VERSION ""

NS_ :

BS_:

BU_: TRAY

BO_ 3221225472 VECTOR__INDEPENDENT_SIG_MSG: 0 Vector__XXX
 SG_ Cellbal_14 : 0|1@0+ (1,0) [0|1] "" Vector__XXX
 SG_ Cellbal_13 : 0|1@0+ (1,0) [0|1] "" Vector__XXX
 SG_ Cellbal_12 : 0|1@0+ (1,0) [0|1] "" Vector__XXX
 SG_ Cellbal_11 : 0|1@0+ (1,0) [0|1] "" Vector__XXX
 SG_ Cellbal_10 : 0|1@0+ (1,0) [0|1] "" Vector__XXX
 SG_ Cellbal_09 : 0|1@0+ (1,0) [0|1] "" Vector__XXX
 SG_ Cellbal_08 : 0|1@0+ (1,0) [0|1] "" Vector__XXX
 SG_ Cellbal_07 : 0|1@0+ (1,0) [0|1] "" Vector__XXX
 SG_ Cellbal_06 : 0|1@0+ (1,0) [0|1] "" Vector__XXX
 SG_ Cellbal_05 : 0|1@0+ (1,0) [0|1] "" Vector__XXX
 SG_ Cellbal_04 : 0|1@0+ (1,0) [0|1] "" Vector__XXX
 SG_ Cellbal_03 : 0|1@0+ (1,0) [0|1] "" Vector__XXX
 SG_ Cellbal_02 : 0|1@0+ (1,0) [0|1] "" Vector__XXX
 SG_ Cellbal_01 : 0|1@0+ (1,0) [0|1] "" Vector__XXX
 SG_ Cellbal_15 : 0|1@0+ (1,0) [0|1] "" Vector__XXX
 SG_ Cellbal_14 : 0|1@0+ (1,0) [0|1] "" Vector__XXX
 SG_ Cellbal_13 : 0|1@0+ (1,0) [0|1] "" Vector__XXX
 SG_ Cellbal_12 : 0|1@0+ (1,0) [0|1] "" Vector__XXX
 SG_ Cellbal_11 : 0|1@0+ (1,0) [0|1] "" Vector__XXX
 SG_ Cellbal_10 : 0|1@0+ (1,0) [0|1] "" Vector__XXX
 SG_ Cellbal_09 : 0|1@0+ (1,0) [0|1] "" Vector__XXX
 SG_ Cellbal_08 : 0|1@0+ (1,0) [0|1] "" Vector__XXX
 SG_ Cellbal_07 : 0|1@0+ (1,0) [0|1] "" Vector__XXX
 SG_ Cellbal_06 : 0|1@0+ (1,0) [0|1] "" Vector__XXX
 SG_ Cellbal_05 : 0|1@0+ (1,0) [0|1] "" Vector__XXX
 SG_ Cellbal_04 : 0|1@0+ (1,0) [0|1] "" Vector__XXX
 SG_ Cellbal_03 : 0|1@0+ (1,0) [0|1] "" Vector__XXX
 SG_ Cellbal_02 : 0|1@0+ (1,0) [0|1] "" Vector__XXX
 SG_ Cellbal_01 : 0|1@0+ (1,0) [0|1] "" Vector__XXX
 SG_ Cellbal_15 : 0|1@0+ (1,0) [0|1] "" Vector__XXX
 SG_ Cellbal_14 : 0|1@0+ (1,0) [0|1] "" Vector__XXX
 SG_ Cellbal_13 : 0|1@0+ (1,0) [0|1] "" Vector__XXX
 SG_ Cellbal_12 : 0|1@0+ (1,0) [0|1] "" Vector__XXX
 SG_ Cellbal_11 : 0|1@0+ (1,0) [0|1] "" Vector__XXX
 SG_ Cellbal_10 : 0|1@0+ (1,0) [0|1] "" Vector__XXX
 SG_ Cellbal_09 : 0|1@0+ (1,0) [0|1] "" Vector__XXX
 SG_ Cellbal_08 : 0|1@0+ (1,0) [0|1] "" Vector__XXX
 SG_ Cellbal_07 : 0|1@0+ (1,0) [0|1] "" Vector__XXX
 SG_ Cellbal_06 : 0|1@0+ (1,0) [0|1] "" Vector__XXX
 SG_ Cellbal_05 : 0|1@0+ (1,0) [0|1] "" Vector__XXX
 SG_ Cellbal_04 : 0|1@0+ (1,0) [0|1] "" Vector__XXX
 SG_ Cellbal_03 : 0|1@0+ (1,0) [0|1] "" Vector__XXX
 SG_ Cellbal_02 : 0|1@0+ (1,0) [0|1] "" Vector__XXX
 SG_ Cellbal_01 : 0|1@0+ (1,0) [0|1] "" Vector__XXX
 SG_ Cellbal_15 : 0|1@0+ (1,0) [0|1] "" Vector__XXX
 SG_ Cellbal_14 : 0|1@0+ (1,0) [0|1] "" Vector__XXX
 SG_ Cellbal_13 : 0|1@0+ (1,0) [0|1] "" Vector__XXX
 SG_ Cellbal_12 : 0|1@0+ (1,0) [0|1] "" Vector__XXX
 SG_ Cellbal_11 : 0|1@0+ (1,0) [0|1] "" Vector__XXX
 SG_ Cellbal_10 : 0|1@0+ (1,0) [0|1] "" Vector__XXX
 SG_ Cellbal_09 : 0|1@0+ (1,0) [0|1] "" Vector__XXX
 SG_ Cellbal_08 : 0|1@0+ (1,0) [0|1] "" Vector__XXX
 SG_ Cellbal_07 : 0|1@0+ (1,0) [0|1] "" Vector__XXX
 SG_ Cellbal_06 : 0|1@0+ (1,0) [0|1] "" Vector__XXX
 SG_ Cellbal_05 : 0|1@0+ (1,0) [0|1] "" Vector__XXX
 SG_ Cellbal_04 : 0|1@0+ (1,0) [0|1] "" Vector__XXX
 SG_ Cellbal_03 : 0|1@0+ (1,0) [0|1] "" Vector__XXX
 SG_ Cellbal_02 : 0|1@0+ (1,0) [0|1] "" Vector__XXX
 SG_ Cellbal_01 : 0|1@0+ (1,0) [0|1] "" Vector__XXX
 SG_ Cellbal_15 : 0|1@0+ (1,0) [0|1] "" Vector__XXX
 SG_ Cellbal_14 : 0|1@0+ (1,0) [0|1] "" Vector__XXX
 SG_ Cellbal_13 : 0|1@0+ (1,0) [0|1] "" Vector__XXX
 SG_ Cellbal_12 : 0|1@0+ (1,0) [0|1] "" Vector__XXX
 SG_ Cellbal_11 : 0|1@0+ (1,0) [0|1] "" Vector__XXX
 SG_ Cellbal_10 : 0|1@0+ (1,0) [0|1] "" Vector__XXX
 SG_ Cellbal_09 : 0|1@0+ (1,0) [0|1] "" Vector__XXX
 SG_ Cellbal_08 : 0|1@0+ (1,0) [0|1] "" Vector__XXX
 SG_ Cellbal_07 : 0|1@0+ (1,0) [0|1] "" Vector__XXX
 SG_ Cellbal_06 : 0|1@0+ (1,0) [0|1] "" Vector__XXX
 SG_ Cellbal_05 : 0|1@0+ (1,0) [0|1] "" Vector__XXX
 SG_ Cellbal_04 : 0|1@0+ (1,0) [0|1] "" Vector__XXX
 SG_ Cellbal_03 : 0|1@0+ (1,0) [0|1] "" Vector__XXX
 SG_ Cellbal_02 : 0|1@0+ (1,0) [0|1] "" Vector__XXX
 SG_ Cellbal_01 : 0|1@0+ (1,0) [0|1] "" Vector__XXX
 SG_ Cellbal_15 : 0|1@0+ (1,0) [0|1] "" Vector__XXX
 SG_ Cellbal_14 : 0|1@0+ (1,0) [0|1] "" Vector__XXX
 SG_ Cellbal_13 : 0|1@0+ (1,0) [0|1] "" Vector__XXX
 SG_ Cellbal_12 : 0|1@0+ (1,0) [0|1] "" Vector__XXX
 SG_ Cellbal_11 : 0|1@0+ (1,0) [0|1] "" Vector__XXX
 SG_ Cellbal_10 : 0|1@0+ (1,0) [0|1] "" Vector__XXX
 SG_ Cellbal_09 : 0|1@0+ (1,0) [0|1] "" Vector__XXX
 SG_ Cellbal_08 : 0|1@0+ (1,0) [0|1] "" Vector__XXX
 SG_ Cellbal_07 : 0|1@0+ (1,0) [0|1] "" Vector__XXX
 SG_ Cellbal_06 : 0|1@0+ (1,0) [0|1] "" Vector__XXX
 SG_ Cellbal_05 : 0|1@0+ (1,0) [0|1] "" Vector__XXX
 SG_ Cellbal_04 : 0|1@0+ (1,0) [0|1] "" Vector__XXX
 SG_ Cellbal_03 : 0|1@0+ (1,0) [0|1] "" Vector__XXX
 SG_ Cellbal_02 : 0|1@0+ (1,0) [0|1] "" Vector__XXX
 SG_ Cellbal_01 : 0|1@0+ (1,0) [0|1] "" Vector__XXX
 SG_ Cellbal_15 : 0|1@0+ (1,0) [0|1] "" Vector__XXX
 SG_ Cellbal_14 : 0|1@0+ (1,0) [0|1] "" Vector__XXX
 SG_ Cellbal_13 : 0|1@0+ (1,0) [0|1] "" Vector__XXX
 SG_ Cellbal_12 : 0|1@0+ (1,0) [0|1] "" Vector__XXX
 SG_ Cellbal_11 : 0|1@0+ (1,0) [0|1] "" Vector__XXX
 SG_ Cellbal_10 : 0|1@0+ (1,0) [0|1] "" Vector__XXX
 SG_ Cellbal_09 : 0|1@0+ (1,0) [0|1] "" Vector__XXX
 SG_ Cellbal_08 : 0|1@0+ (1,0) [0|1] "" Vector__XXX
 SG_ Cellbal_07 : 0|1@0+ (1,0) [0|1] "" Vector__XXX
 SG_ Cellbal_06 : 0|1@0+ (1,0) [0|1] "" Vector__XXX
 SG_ Cellbal_05 : 0|1@0+ (1,0) [0|1] "" Vector__XXX
 SG_ Cellbal_04 : 0|1@0+ (1,0) [0|1] "" Vector__XXX
 SG_ Cellbal_03 : 0|1@0+ (1,0) [0|1] "" Vector__XXX
 SG_ Cellbal_02 : 0|1@0+ (1,0) [0|1] "" Vector__XXX
 SG_ Cellbal_01 : 0|1@0+ (1,0) [0|1] "" Vector__XXX
 SG_ Cellbal_15 : 0|1@0+ (1,0) [0|1] "" Vector__XXX
 SG_ Cellbal_14 : 0|1@0+ (1,0) [0|1] "" Vector__XXX
 SG_ Cellbal_13 : 0|1@0+ (1,0) [0|1] "" Vector__XXX
 SG_ Cellbal_12 : 0|1@0+ (1,0) [0|1] "" Vector__XXX
 SG_ Cellbal_11 : 0|1@0+ (1,0) [0|1] "" Vector__XXX
 SG_ Cellbal_10 : 0|1@0+ (1,0) [0|1] "" Vector__XXX
 SG_ Cellbal_09 : 0|1@0+ (1,0) [0|1] "" Vector__XXX
 SG_ Cellbal_08 : 0|1@0+ (1,0) [0|1] "" Vector__XXX
 SG_ Cellbal_07 : 0|1@0+ (1,0) [0|1] "" Vector__XXX
 SG_ Cellbal_06 : 0|1@0+ (1,0) [0|1] "" Vector__XXX
 SG_ Cellbal_05 : 0|1@0+ (1,0) [0|1] "" Vector__XXX
 SG_ Cellbal_04 : 0|1@0+ (1,0) [0|1] "" Vector__XXX
 SG_ Cellbal_03 : 0|1@0+ (1,0) [0|1] "" Vector__XXX
 SG_ Cellbal_02 : 0|1@0+ (1,0) [0|1] "" Vector__XXX
 SG_ Cellbal_01 : 0|1@0+ (1,0) [0|1] "" Vector__XXX
 SG_ Cellbal_15 : 0|1@0+ (1,0) [0|1] "" Vector__XXX
 SG_ Cellbal_14 : 0|1@0+ (1,0) [0|1] "" Vector__XXX
 SG_ Cellbal_13 : 0|1@0+ (1,0) [0|1] "" Vector__XXX
 SG_ Cellbal_12 : 0|1@0+ (1,0) [0|1] "" Vector__XXX
 SG_ Cellbal_11 : 0|1@0+ (1,0) [0|1] "" Vector__XXX
 SG_ Cellbal_10 : 0|1@0+ (1,0) [0|1] "" Vector__XXX
 SG_ Cellbal_09 : 0|1@0+ (1,0) [0|1] "" Vector__XXX
 SG_ Cellbal_08 : 0|1@0+ (1,0) [0|1] "" Vector__XXX
 SG_ Cellbal_07 : 0|1@0+ (1,0) [0|1] "" Vector__XXX
 SG_ Cellbal_06 : 0|1@0+ (1,0) [0|1] "" Vector__XXX
 SG_ Cellbal_05 : 0|1@0+ (1,0) [0|1] "" Vector__XXX
 SG_ Cellbal_04 : 0|1@0+ (1,0) [0|1] "" Vector__XXX
 SG_ Cellbal_03 : 0|1@0+ (1,0) [0|1] "" Vector__XXX
 SG_ Cellbal_02 : 0|1@0+ (1,0) [0|1] "" Vector__XXX
 SG_ Cellbal_01 : 0|1@0+ (1,0) [0|1] "" Vector__XXX
 SG_ Cellbal_15 : 0|1@0+ (1,0) [0|1] "" Vector__XXX
 SG_ Cellbal_14 : 0|1@0+ (1,0) [0|1] "" Vector__XXX
 SG_ Cellbal_13 : 0|1@0+ (1,0) [0|1] "" Vector__XXX
 SG_ Cellbal_12 : 0|1@0+ (1,0) [0|1] "" Vector__XXX
 SG_ Cellbal_11 : 0|1@0+ (1,0) [0|1] "" Vector__XXX
 SG_ Cellbal_10 : 0|1@0+ (1,0) [0|1] "" Vector__XXX
 SG_ Cellbal_09 : 0|1@0+ (1,0) [0|1] "" Vector__XXX
 SG_ Cellbal_08 : 0|1@0+ (1,0) [0|1] "" Vector__XXX
 SG_ Cellbal_07 : 0|1@0+ (1,0) [0|1] "" Vector__XXX
 SG_ Cellbal_06 : 0|1@0+ (1,0) [0|1] "" Vector__XXX
 SG_ Cellbal_05 : 0|1@0+ (1,0) [0|1] "" Vector__XXX
 SG_ Cellbal_04 : 0|1@0+ (1,0) [0|1] "" Vector__XXX
 SG_ Cellbal_03 : 0|1@0+ (1,0) [0|1] "" Vector__XXX
 SG_ Cellbal_02 : 0|1@0+ (1,0) [0|1] "" Vector__XXX
 SG_ Cellbal_01 : 0|1@0+ (1,0) [0|1] "" Vector__XXX
 SG_ Cellbal_15 : 0|1@0+ (1,0) [0|1] "" Vector__XXX
 SG_ Cellbal_14 : 0|1@0+ (1,0) [0|1] "" Vector__XXX
 SG_ Cellbal_13 : 0|1@0+ (1,0) [0|1] "" Vector__XXX
 SG_ Cellbal_12 : 0|1@0+ (1,0) [0|1] "" Vector__XXX
 SG_ Cellbal_11 : 0|1@0+ (1,0) [0|1] "" Vector__XXX
 SG_ Cellbal_10 : 0|1@0+ (1,0) [0|1] "" Vector__XXX
 SG_ Cellbal_09 : 0|1@0+ (1,0) [0|1] "" Vector__XXX
 SG_ Cellbal_08 : 0|1@0+ (1,0) [0|1] "" Vector__XXX
 SG_ Cellbal_07 : 0|1@0+ (1,0) [0|1] "" Vector__XXX
 SG_ Cellbal_06 : 0|1@0+ (1,0) [0|1] "" Vector__XXX
 SG_ Cellbal_05 : 0|1@0+ (1,0) [0|1] "" Vector__XXX
 SG_ Cellbal_04 : 0|1@0+ (1,0) [0|1] "" Vector__XXX
 SG_ Cellbal_03 : 0|1@0+ (1,0) [0|1] "" Vector__XXX
 SG_ Cellbal_02 : 0|1@0+ (1,0) [0|1] "" Vector__XXX
 SG_ Cellbal_01 : 0|1@0+ (1,0) [0|1] "" Vector__XXX
 SG_ Cellbal_15 : 0|1@0+ (1,0) [0|1] "" Vector__XXX
 SG_ Cellbal_14 : 0|1@0+ (1,0) [0|1] "" Vector__XXX
 SG_ Cellbal_13 : 0|1@0+ (1,0) [0|1] "" Vector__XXX
 SG_ Cellbal_12 : 0|1@0+ (1,0) [0|1] "" Vector__XXX
 SG_ Cellbal_11 : 0|1@0+ (1,0) [0|1] "" Vector__XXX
 SG_ Cellbal_10 : 0|1@0+ (1,0) [0|1] "" Vector__XXX
 SG_ Cellbal_09 : 0|1@0+ (1,0) [0|1] "" Vector__XXX
 SG_ Cellbal_08 : 0|1@0+ (1,0) [0|1] "" Vector__XXX
 SG_ Cellbal_07 : 0|1@0+ (1,0) [0|1] "" Vector__XXX
 SG_ Cellbal_06 : 0|1@0+ (1,0) [0|1] "" Vector__XXX
 SG_ Cellbal_05 : 0|1@0+ (1,0) [0|1] "" Vector__XXX
 SG_ Cellbal_04 : 0|1@0+ (1,0) [0|1] "" Vector__XXX
 SG_ Cellbal_03 : 0|1@0+ (1,0) [0|1] "" Vector__XXX
 SG_ Cellbal_02 : 0|1@0+ (1,0) [0|1] "" Vector__XXX
 SG_ Cellbal_01 : 0|1@0+ (1,0) [0|1] "" Vector__XXX
 SG_ Cellbal_15 : 0|1@0+ (1,0) [0|1] "" Vector__XXX
 SG_ Cellbal_14 : 0|1@0+ (1,0) [0|1] "" Vector__XXX
 SG_ Cellbal_13 : 0|1@0+ (1,0) [0|1] "" Vector__XXX
 SG_ Cellbal_12 : 0|1@0+ (1,0) [0|1] "" Vector__XXX
 SG_ Cellbal_11 : 0|1@0+ (1,0) [0|1] "" Vector__XXX
 SG_ Cellbal_10 : 0|1@0+ (1,0) [0|1] "" Vector__XXX
 SG_ Cellbal_09 : 0|1@0+ (1,0) [0|1] "" Vector__XXX
 SG_ Cellbal_08 : 0|1@0+ (1,0) [0|1] "" Vector__XXX
 SG_ Cellbal_07 : 0|1@0+ (1,0) [0|1] "" Vector__XXX
 SG_ Cellbal_06 : 0|1@0+ (1,0) [0|1] "" Vector__XXX
 SG_ Cellbal_05 : 0|1@0+ (1,0) [0|1] "" Vector__XXX
 SG_ Cellbal_04 : 0|1@0+ (1,0) [0|1] "" Vector__XXX
 SG_ Cellbal_03 : 0|1@0+ (1,0) [0|1] "" Vector__XXX
 SG_ Cellbal_02 : 0|1@0+ (1,0) [0|1] "" Vector__XXX
 SG_ Cellbal_01 : 0|1@0+ (1,0) [0|1] "" Vector__XXX
 SG_ Cellbal_15 : 0|1@0+ (1,0) [0|1] "" Vector__XXX
 SG_ brdtemp2 : 0|16@0- (1,0) [0|0] "" Vector__XXX
 SG_ brdtemp1 : 0|16@0- (1,0) [0|0] "" Vector__XXX
 SG_ temp2 : 0|16@0- (1,0) [0|0] "" Vector__XXX
 SG_ temp1 : 0|16@0- (1,0) [0|0] "" Vector__XXX
 SG_ brdtemp2 : 0|16@0- (1,0) [0|0] "" Vector__XXX
 SG_ brdtemp1 : 0|16@0- (1,0) [0|0] "" Vector__XXX
 SG_ temp2 : 0|16@0- (1,0) [0|0] "" Vector__XXX
 SG_ temp1 : 0|16@0- (1,0) [0|0] "" Vector__XXX
 SG_ brdtemp2 : 0|16@0- (1,0) [0|0] "" Vector__XXX
 SG_ brdtemp1 : 0|16@0- (1,0) [0|0] "" Vector__XXX
 SG_ temp2 : 0|16@0- (1,0) [0|0] "" Vector__XXX
 SG_ temp1 : 0|16@0- (1,0) [0|0] "" Vector__XXX
 SG_ brdtemp2 : 0|16@0- (1,0) [0|0] "" Vector__XXX
 SG_ brdtemp1 : 0|16@0- (1,0) [0|0] "" Vector__XXX
 SG_ temp2 : 0|16@0- (1,0) [0|0] "" Vector__XXX
 SG_ temp1 : 0|16@0- (1,0) [0|0] "" Vector__XXX
 SG_ brdtemp2 : 0|16@0- (1,0) [0|0] "" Vector__XXX
 SG_ brdtemp1 : 0|16@0- (1,0) [0|0] "" Vector__XXX
 SG_ temp2 : 0|16@0- (1,0) [0|0] "" Vector__XXX
 SG_ temp1 : 0|16@0- (1,0) [0|0] "" Vector__XXX
 SG_ brdtemp2 : 0|16@0- (1,0) [0|0] "" Vector__XXX
 SG_ brdtemp1 : 0|16@0- (1,0) [0|0] "" Vector__XXX
 SG_ temp2 : 0|16@0- (1,0) [0|0] "" Vector__XXX
 SG_ temp1 : 0|16@0- (1,0) [0|0] "" Vector__XXX
 SG_ brdtemp2 : 0|16@0- (1,0) [0|0] "" Vector__XXX
 SG_ brdtemp1 : 0|16@0- (1,0) [0|0] "" Vector__XXX
 SG_ temp2 : 0|16@0- (1,0) [0|0] "" Vector__XXX
 SG_ temp1 : 0|16@0- (1,0) [0|0] "" Vector__XXX
 SG_ brdtemp2 : 0|16@0- (1,0) [0|0] "" Vector__XXX
 SG_ brdtemp1 : 0|16@0- (1,0) [0|0] "" Vector__XXX
 SG_ temp2 : 0|16@0- (1,0) [0|0] "" Vector__XXX
 SG_ temp1 : 0|16@0- (1,0) [0|0] "" Vector__XXX
 SG_ brdtemp2 : 0|16@0- (1,0) [0|0] "" Vector__XXX
 SG_ brdtemp1 : 0|16@0- (1,0) [0|0] "" Vector__XXX
 SG_ temp2 : 0|16@0- (1,0) [0|0] "" Vector__XXX
 SG_ temp1 : 0|16@0- (1,0) [0|0] "" Vector__XXX
 SG_ brdtemp2 : 0|16@0- (1,0) [0|0] "" Vector__XXX
 SG_ brdtemp1 : 0|16@0- (1,0) [0|0] "" Vector__XXX
 SG_ temp2 : 0|16@0- (1,0) [0|0] "" Vector__XXX
 SG_ temp1 : 0|16@0- (1,0) [0|0] "" Vector__XXX
 SG_ brdtemp2 : 0|16@0- (1,0) [0|0] "" Vector__XXX
 SG_ brdtemp1 : 0|16@0- (1,0) [0|0] "" Vector__XXX
 SG_ temp2 : 0|16@0- (1,0) [0|0] "" Vector__XXX
 SG_ temp1 : 0|16@0- (1,0) [0|0] "" Vector__XXX
 SG_ brdtemp2 : 0|16@0- (1,0) [0|0] "" Vector__XXX
 SG_ brdtemp1 : 0|16@0- (1,0) [0|0] "" Vector__XXX
 SG_ temp2 : 0|16@0- (1,0) [0|0] "" Vector__XXX
 SG_ cell15 : 0|16@0+ (1,0) [0|5000] "V" Vector__XXX
 SG_ cell14 : 0|16@0+ (1,0) [0|5000] "V" Vector__XXX
 SG_ cell13 : 0|16@0+ (1,0) [0|5000] "V" Vector__XXX
 SG_ cell15 : 0|16@0+ (1,0) [0|5000] "V" Vector__XXX
 SG_ cell14 : 0|16@0+ (1,0) [0|5000] "V" Vector__XXX
 SG_ cell13 : 0|16@0+ (1,0) [0|5000] "V" Vector__XXX
 SG_ cell15 : 0|16@0+ (1,0) [0|5000] "V" Vector__XXX
 SG_ cell14 : 0|16@0+ (1,0) [0|5000] "V" Vector__XXX
 SG_ cell13 : 0|16@0+ (1,0) [0|5000] "V" Vector__XXX
 SG_ cell15 : 0|16@0+ (1,0) [0|5000] "V" Vector__XXX
 SG_ cell14 : 0|16@0+ (1,0) [0|5000] "V" Vector__XXX
 SG_ cell13 : 0|16@0+ (1,0) [0|5000] "V" Vector__XXX
 SG_ cell15 : 0|16@0+ (1,0) [0|5000] "V" Vector__XXX
 SG_ cell14 : 0|16@0+ (1,0) [0|5000] "V" Vector__XXX
 SG_ cell13 : 0|16@0+ (1,0) [0|5000] "V" Vector__XXX
 SG_ cell15 : 0|16@0+ (1,0) [0|5000] "V" Vector__XXX
 SG_ cell14 : 0|16@0+ (1,0) [0|5000] "V" Vector__XXX
 SG_ cell13 : 0|16@0+ (1,0) [0|5000] "V" Vector__XXX
 SG_ cell15 : 0|16@0+ (1,0) [0|5000] "V" Vector__XXX
 SG_ cell14 : 0|16@0+ (1,0) [0|5000] "V" Vector__XXX
 SG_ cell13 : 0|16@0+ (1,0) [0|5000] "V" Vector__XXX
 SG_ cell15 : 0|16@0+ (1,0) [0|5000] "V" Vector__XXX
 SG_ cell14 : 0|16@0+ (1,0) [0|5000] "V" Vector__XXX
 SG_ cell13 : 0|16@0+ (1,0) [0|5000] "V" Vector__XXX
 SG_ cell15 : 0|16@0+ (1,0) [0|5000] "V" Vector__XXX
 SG_ cell14 : 0|16@0+ (1,0) [0|5000] "V" Vector__XXX
 SG_ cell13 : 0|16@0+ (1,0) [0|5000] "V" Vector__XXX
 SG_ cell15 : 0|16@0+ (1,0) [0|5000] "V" Vector__XXX
 SG_ cell14 : 0|16@0+ (1,0) [0|5000] "V" Vector__XXX
 SG_ cell13 : 0|16@0+ (1,0) [0|5000] "V" Vector__XXX
 SG_ cell15 : 0|16@0+ (1,0) [0|5000] "V" Vector__XXX
 SG_ cell14 : 0|16@0+ (1,0) [0|5000] "V" Vector__XXX
 SG_ cell13 : 0|16@0+ (1,0) [0|5000] "V" Vector__XXX
 SG_ cell15 : 0|16@0+ (1,0) [0|5000] "V" Vector__XXX
 SG_ cell14 : 0|16@0+ (1,0) [0|5000] "V" Vector__XXX
 SG_ cell13 : 0|16@0+ (1,0) [0|5000] "V" Vector__XXX
 SG_ cell12 : 0|16@0+ (1,0) [0|5000] "V" Vector__XXX
 SG_ cell11 : 0|16@0+ (1,0) [0|5000] "V" Vector__XXX
 SG_ cell10 : 0|16@0+ (1,0) [0|5000] "V" Vector__XXX
 SG_ cell9 : 0|16@0+ (1,0) [0|5000] "V" Vector__XXX
 SG_ cell12 : 0|16@0+ (1,0) [0|5000] "V" Vector__XXX
 SG_ cell11 : 0|16@0+ (1,0) [0|5000] "V" Vector__XXX
 SG_ cell10 : 0|16@0+ (1,0) [0|5000] "V" Vector__XXX
 SG_ cell9 : 0|16@0+ (1,0) [0|5000] "V" Vector__XXX
 SG_ cell12 : 0|16@0+ (1,0) [0|5000] "V" Vector__XXX
 SG_ cell11 : 0|16@0+ (1,0) [0|5000] "V" Vector__XXX
 SG_ cell10 : 0|16@0+ (1,0) [0|5000] "V" Vector__XXX
 SG_ cell9 : 0|16@0+ (1,0) [0|5000] "V" Vector__XXX
 SG_ cell12 : 0|16@0+ (1,0) [0|5000] "V" Vector__XXX
 SG_ cell11 : 0|16@0+ (1,0) [0|5000] "V" Vector__XXX
 SG_ cell10 : 0|16@0+ (1,0) [0|5000] "V" Vector__XXX
 SG_ cell9 : 0|16@0+ (1,0) [0|5000] "V" Vector__XXX
 SG_ cell12 : 0|16@0+ (1,0) [0|5000] "V" Vector__XXX
 SG_ cell11 : 0|16@0+ (1,0) [0|5000] "V" Vector__XXX
 SG_ cell10 : 0|16@0+ (1,0) [0|5000] "V" Vector__XXX
 SG_ cell9 : 0|16@0+ (1,0) [0|5000] "V" Vector__XXX
 SG_ cell12 : 0|16@0+ (1,0) [0|5000] "V" Vector__XXX
 SG_ cell11 : 0|16@0+ (1,0) [0|5000] "V" Vector__XXX
 SG_ cell10 : 0|16@0+ (1,0) [0|5000] "V" Vector__XXX
 SG_ cell9 : 0|16@0+ (1,0) [0|5000] "V" Vector__XXX
 SG_ cell12 : 0|16@0+ (1,0) [0|5000] "V" Vector__XXX
 SG_ cell11 : 0|16@0+ (1,0) [0|5000] "V" Vector__XXX
 SG_ cell10 : 0|16@0+ (1,0) [0|5000] "V" Vector__XXX
 SG_ cell9 : 0|16@0+ (1,0) [0|5000] "V" Vector__XXX
 SG_ cell12 : 0|16@0+ (1,0) [0|5000] "V" Vector__XXX
 SG_ cell11 : 0|16@0+ (1,0) [0|5000] "V" Vector__XXX
 SG_ cell10 : 0|16@0+ (1,0) [0|5000] "V" Vector__XXX
 SG_ cell9 : 0|16@0+ (1,0) [0|5000] "V" Vector__XXX
 SG_ cell12 : 0|16@0+ (1,0) [0|5000] "V" Vector__XXX
 SG_ cell11 : 0|16@0+ (1,0) [0|5000] "V" Vector__XXX
 SG_ cell10 : 0|16@0+ (1,0) [0|5000] "V" Vector__XXX
 SG_ cell9 : 0|16@0+ (1,0) [0|5000] "V" Vector__XXX
 SG_ cell12 : 0|16@0+ (1,0) [0|5000] "V" Vector__XXX
 SG_ cell11 : 0|16@0+ (1,0) [0|5000] "V" Vector__XXX
 SG_ cell10 : 0|16@0+ (1,0) [0|5000] "V" Vector__XXX
 SG_ cell9 : 0|16@0+ (1,0) [0|5000] "V" Vector__XXX
 SG_ cell12 : 0|16@0+ (1,0) [0|5000] "V" Vector__XXX
 SG_ cell11 : 0|16@0+ (1,0) [0|5000] "V" Vector__XXX
 SG_ cell10 : 0|16@0+ (1,0) [0|5000] "V" Vector__XXX
 SG_ cell9 : 0|16@0+ (1,0) [0|5000] "V" Vector__XXX
 SG_ cell12 : 0|16@0+ (1,0) [0|5000] "V" Vector__XXX
 SG_ cell11 : 0|16@0+ (1,0) [0|5000] "V" Vector__XXX
 SG_ cell10 : 0|16@0+ (1,0) [0|5000] "V" Vector__XXX
 SG_ cell9 : 0|16@0+ (1,0) [0|5000] "V" Vector__XXX
 SG_ cell8 : 0|16@0+ (1,0) [0|5000] "V" Vector__XXX
 SG_ cell7 : 0|16@0+ (1,0) [0|5000] "V" Vector__XXX
 SG_ cell6 : 0|16@0+ (1,0) [0|5000] "V" Vector__XXX
 SG_ cell5 : 0|16@0+ (1,0) [0|5000] "V" Vector__XXX
 SG_ cell8 : 0|16@0+ (1,0) [0|5000] "V" Vector__XXX
 SG_ cell7 : 0|16@0+ (1,0) [0|5000] "V" Vector__XXX
 SG_ cell6 : 0|16@0+ (1,0) [0|5000] "V" Vector__XXX
 SG_ cell5 : 0|16@0+ (1,0) [0|5000] "V" Vector__XXX
 SG_ cell8 : 0|16@0+ (1,0) [0|5000] "V" Vector__XXX
 SG_ cell7 : 0|16@0+ (1,0) [0|5000] "V" Vector__XXX
 SG_ cell6 : 0|16@0+ (1,0) [0|5000] "V" Vector__XXX
 SG_ cell5 : 0|16@0+ (1,0) [0|5000] "V" Vector__XXX
 SG_ cell8 : 0|16@0+ (1,0) [0|5000] "V" Vector__XXX
 SG_ cell7 : 0|16@0+ (1,0) [0|5000] "V" Vector__XXX
 SG_ cell6 : 0|16@0+ (1,0) [0|5000] "V" Vector__XXX
 SG_ cell5 : 0|16@0+ (1,0) [0|5000] "V" Vector__XXX
 SG_ cell8 : 0|16@0+ (1,0) [0|5000] "V" Vector__XXX
 SG_ cell7 : 0|16@0+ (1,0) [0|5000] "V" Vector__XXX
 SG_ cell6 : 0|16@0+ (1,0) [0|5000] "V" Vector__XXX
 SG_ cell5 : 0|16@0+ (1,0) [0|5000] "V" Vector__XXX
 SG_ cell8 : 0|16@0+ (1,0) [0|5000] "V" Vector__XXX
 SG_ cell7 : 0|16@0+ (1,0) [0|5000] "V" Vector__XXX
 SG_ cell6 : 0|16@0+ (1,0) [0|5000] "V" Vector__XXX
 SG_ cell5 : 0|16@0+ (1,0) [0|5000] "V" Vector__XXX
 SG_ cell8 : 0|16@0+ (1,0) [0|5000] "V" Vector__XXX
 SG_ cell7 : 0|16@0+ (1,0) [0|5000] "V" Vector__XXX
 SG_ cell6 : 0|16@0+ (1,0) [0|5000] "V" Vector__XXX
 SG_ cell5 : 0|16@0+ (1,0) [0|5000] "V" Vector__XXX
 SG_ cell8 : 0|16@0+ (1,0) [0|5000] "V" Vector__XXX
 SG_ cell7 : 0|16@0+ (1,0) [0|5000] "V" Vector__XXX
 SG_ cell6 : 0|16@0+ (1,0) [0|5000] "V" Vector__XXX
 SG_ cell5 : 0|16@0+ (1,0) [0|5000] "V" Vector__XXX
 SG_ cell8 : 0|16@0+ (1,0) [0|5000] "V" Vector__XXX
 SG_ cell7 : 0|16@0+ (1,0) [0|5000] "V" Vector__XXX
 SG_ cell6 : 0|16@0+ (1,0) [0|5000] "V" Vector__XXX
 SG_ cell5 : 0|16@0+ (1,0) [0|5000] "V" Vector__XXX
 SG_ cell8 : 0|16@0+ (1,0) [0|65536] "V" Vector__XXX
 SG_ cell7 : 0|16@0+ (1,0) [0|65536] "V" Vector__XXX
 SG_ cell6 : 0|16@0+ (1,0) [0|65536] "V" Vector__XXX
 SG_ cell5 : 0|16@0+ (1,0) [0|65536] "V" Vector__XXX
 SG_ cell8 : 0|16@0+ (1,0) [0|5000] "V" Vector__XXX
 SG_ cell7 : 0|16@0+ (1,0) [0|5000] "V" Vector__XXX
 SG_ cell6 : 0|16@0+ (1,0) [0|5000] "V" Vector__XXX
 SG_ cell5 : 0|16@0+ (1,0) [0|5000] "V" Vector__XXX
 SG_ cell8 : 0|16@0+ (1,0) [0|5000] "V" Vector__XXX
 SG_ cell7 : 0|16@0+ (1,0) [0|5000] "V" Vector__XXX
 SG_ cell6 : 0|16@0+ (1,0) [0|5000] "V" Vector__XXX
 SG_ cell5 : 0|16@0+ (1,0) [0|5000] "V" Vector__XXX
 SG_ cell4 : 0|16@0+ (1,0) [0|5000] "V" Vector__XXX
 SG_ cell3 : 0|16@0+ (1,0) [0|5000] "V" Vector__XXX
 SG_ cell2 : 0|16@0+ (1,0) [0|5000] "V" Vector__XXX
 SG_ cell1 : 0|16@0+ (1,0) [0|5000] "V" Vector__XXX
 SG_ cell4 : 0|16@0+ (1,0) [0|5000] "V" Vector__XXX
 SG_ cell3 : 0|16@0+ (1,0) [0|5000] "V" Vector__XXX
 SG_ cell2 : 0|16@0+ (1,0) [0|5000] "V" Vector__XXX
 SG_ cell1 : 0|16@0+ (1,0) [0|5000] "V" Vector__XXX
 SG_ cell4 : 0|16@0+ (1,0) [0|5000] "V" Vector__XXX
 SG_ cell3 : 0|16@0+ (1,0) [0|5000] "V" Vector__XXX
 SG_ cell2 : 0|16@0+ (1,0) [0|5000] "V" Vector__XXX
 SG_ cell1 : 0|16@0+ (1,0) [0|5000] "V" Vector__XXX
 SG_ cell4 : 0|16@0+ (1,0) [0|5000] "V" Vector__XXX
 SG_ cell3 : 0|16@0+ (1,0) [0|5000] "V" Vector__XXX
 SG_ cell2 : 0|16@0+ (1,0) [0|5000] "V" Vector__XXX
 SG_ cell1 : 0|16@0+ (1,0) [0|5000] "V" Vector__XXX
 SG_ cell4 : 0|16@0+ (1,0) [0|5000] "V" Vector__XXX
 SG_ cell3 : 0|16@0+ (1,0) [0|5000] "V" Vector__XXX
 SG_ cell2 : 0|16@0+ (1,0) [0|5000] "V" Vector__XXX
 SG_ cell1 : 0|16@0+ (1,0) [0|5000] "V" Vector__XXX
 SG_ cell4 : 0|16@0+ (1,0) [0|5000] "V" Vector__XXX
 SG_ cell3 : 0|16@0+ (1,0) [0|5000] "V" Vector__XXX
 SG_ cell2 : 0|16@0+ (1,0) [0|5000] "V" Vector__XXX
 SG_ cell1 : 0|16@0+ (1,0) [0|5000] "V" Vector__XXX
 SG_ cell4 : 0|16@0+ (1,0) [0|5000] "V" Vector__XXX
 SG_ cell3 : 0|16@0+ (1,0) [0|5000] "V" Vector__XXX
 SG_ cell2 : 0|16@0+ (1,0) [0|5000] "V" Vector__XXX
 SG_ cell1 : 0|16@0+ (1,0) [0|5000] "V" Vector__XXX
 SG_ cell4 : 0|16@0+ (1,0) [0|5000] "V" Vector__XXX
 SG_ cell3 : 0|16@0+ (1,0) [0|5000] "V" Vector__XXX
 SG_ cell2 : 0|16@0+ (1,0) [0|5000] "V" Vector__XXX
 SG_ cell1 : 0|16@0+ (1,0) [0|5000] "V" Vector__XXX
 SG_ cell4 : 0|16@0+ (1,0) [0|5000] "V" Vector__XXX
 SG_ cell3 : 0|16@0+ (1,0) [0|5000] "V" Vector__XXX
 SG_ cell2 : 0|16@0+ (1,0) [0|5000] "V" Vector__XXX
 SG_ cell1 : 0|16@0+ (1,0) [0|5000] "V" Vector__XXX
 SG_ cell4 : 0|16@0+ (1,0) [0|5000] "V" Vector__XXX
 SG_ cell3 : 0|16@0+ (1,0) [0|5000] "V" Vector__XXX
 SG_ cell2 : 0|16@0+ (1,0) [0|5000] "V" Vector__XXX
 SG_ cell1 : 0|16@0+ (1,0) [0|5000] "V" Vector__XXX
 SG_ cell4 : 0|16@0+ (1,0) [0|5000] "V" Vector__XXX
 SG_ cell3 : 0|16@0+ (1,0) [0|5000] "V" Vector__XXX
 SG_ cell2 : 0|16@0+ (1,0) [0|5000] "V" Vector__XXX
 SG_ cell1 : 0|16@0+ (1,0) [0|5000] "V" Vector__XXX
 SG_ cell4 : 0|16@0+ (1,0) [0|5000] "V" Vector__XXX
 SG_ cell3 : 0|16@0+ (1,0) [0|5000] "V" Vector__XXX
 SG_ cell2 : 0|16@0+ (1,0) [0|5000] "V" Vector__XXX
 SG_ cell1 : 0|16@0+ (1,0) [0|5000] "V" Vector__XXX

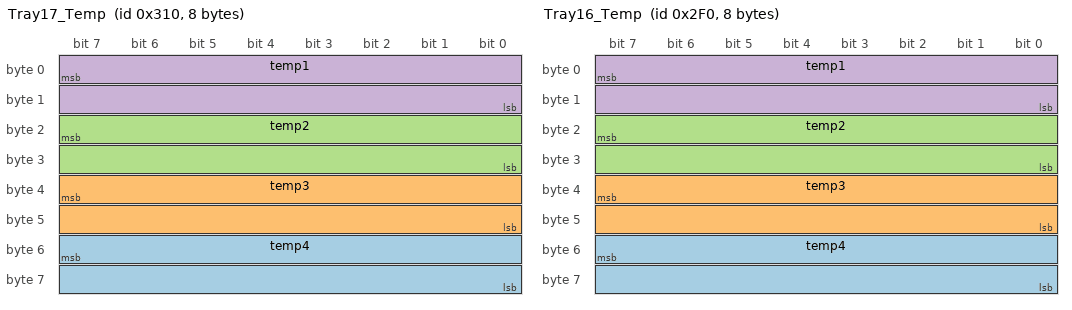
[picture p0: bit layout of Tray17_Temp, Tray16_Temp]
BO_ 784 Tray17_Temp: 8 Vector__XXX
 SG_ temp4 : 55|16@0- (1,0) [0|0] "" Vector__XXX
 SG_ temp3 : 39|16@0- (1,0) [0|0] "" Vector__XXX
 SG_ temp2 : 23|16@0- (1,0) [0|0] "" Vector__XXX
 SG_ temp1 : 7|16@0- (1,0) [0|0] "" Vector__XXX

BO_ 752 Tray16_Temp: 8 Vector__XXX
 SG_ temp4 : 55|16@0- (1,0) [0|0] "" Vector__XXX
 SG_ temp3 : 39|16@0- (1,0) [0|0] "" Vector__XXX
 SG_ temp2 : 23|16@0- (1,0) [0|0] "" Vector__XXX
 SG_ temp1 : 7|16@0- (1,0) [0|0] "" Vector__XXX

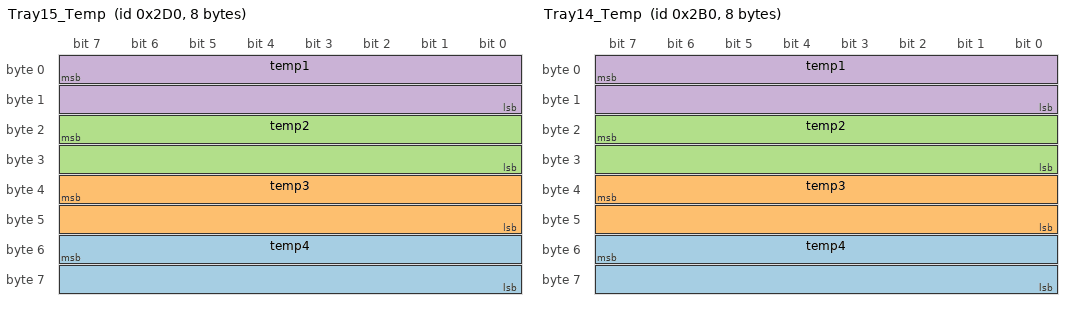
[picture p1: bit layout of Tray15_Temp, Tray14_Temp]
BO_ 720 Tray15_Temp: 8 Vector__XXX
 SG_ temp4 : 55|16@0- (1,0) [0|0] "" Vector__XXX
 SG_ temp3 : 39|16@0- (1,0) [0|0] "" Vector__XXX
 SG_ temp2 : 23|16@0- (1,0) [0|0] "" Vector__XXX
 SG_ temp1 : 7|16@0- (1,0) [0|0] "" Vector__XXX

BO_ 688 Tray14_Temp: 8 Vector__XXX
 SG_ temp4 : 55|16@0- (1,0) [0|0] "" Vector__XXX
 SG_ temp3 : 39|16@0- (1,0) [0|0] "" Vector__XXX
 SG_ temp2 : 23|16@0- (1,0) [0|0] "" Vector__XXX
 SG_ temp1 : 7|16@0- (1,0) [0|0] "" Vector__XXX

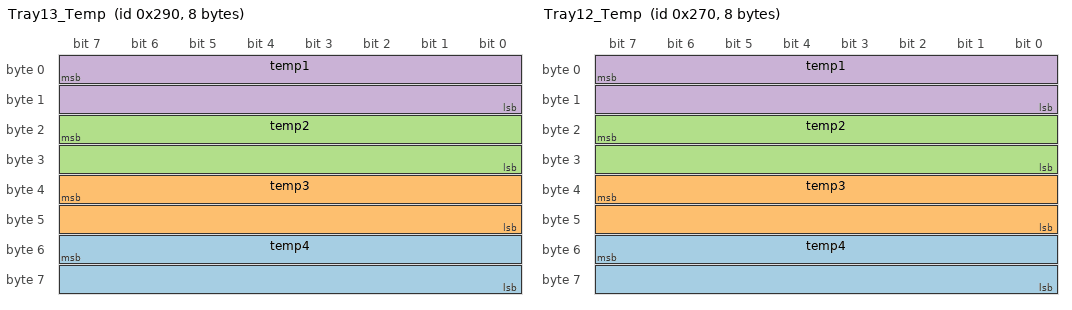
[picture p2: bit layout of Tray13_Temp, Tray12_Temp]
BO_ 656 Tray13_Temp: 8 Vector__XXX
 SG_ temp4 : 55|16@0- (1,0) [0|0] "" Vector__XXX
 SG_ temp3 : 39|16@0- (1,0) [0|0] "" Vector__XXX
 SG_ temp2 : 23|16@0- (1,0) [0|0] "" Vector__XXX
 SG_ temp1 : 7|16@0- (1,0) [0|0] "" Vector__XXX

BO_ 624 Tray12_Temp: 8 Vector__XXX
 SG_ temp4 : 55|16@0- (1,0) [0|0] "" Vector__XXX
 SG_ temp3 : 39|16@0- (1,0) [0|0] "" Vector__XXX
 SG_ temp2 : 23|16@0- (1,0) [0|0] "" Vector__XXX
 SG_ temp1 : 7|16@0- (1,0) [0|0] "" Vector__XXX

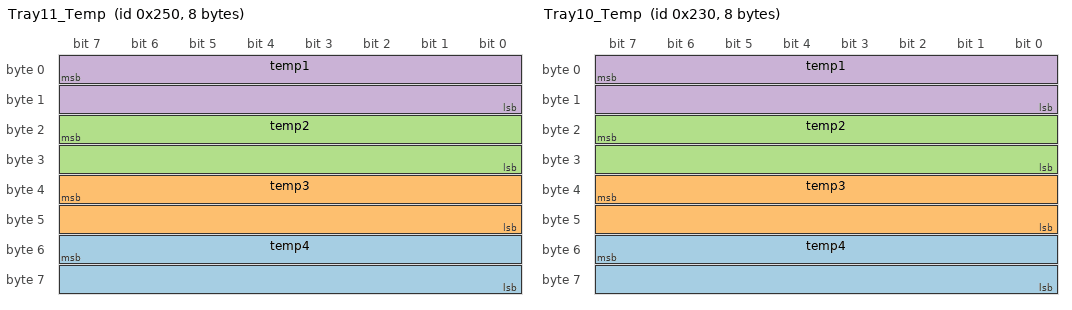
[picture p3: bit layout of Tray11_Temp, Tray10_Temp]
BO_ 592 Tray11_Temp: 8 Vector__XXX
 SG_ temp4 : 55|16@0- (1,0) [0|0] "" Vector__XXX
 SG_ temp3 : 39|16@0- (1,0) [0|0] "" Vector__XXX
 SG_ temp2 : 23|16@0- (1,0) [0|0] "" Vector__XXX
 SG_ temp1 : 7|16@0- (1,0) [0|0] "" Vector__XXX

BO_ 560 Tray10_Temp: 8 Vector__XXX
 SG_ temp4 : 55|16@0- (1,0) [0|0] "" Vector__XXX
 SG_ temp3 : 39|16@0- (1,0) [0|0] "" Vector__XXX
 SG_ temp2 : 23|16@0- (1,0) [0|0] "" Vector__XXX
 SG_ temp1 : 7|16@0- (1,0) [0|0] "" Vector__XXX

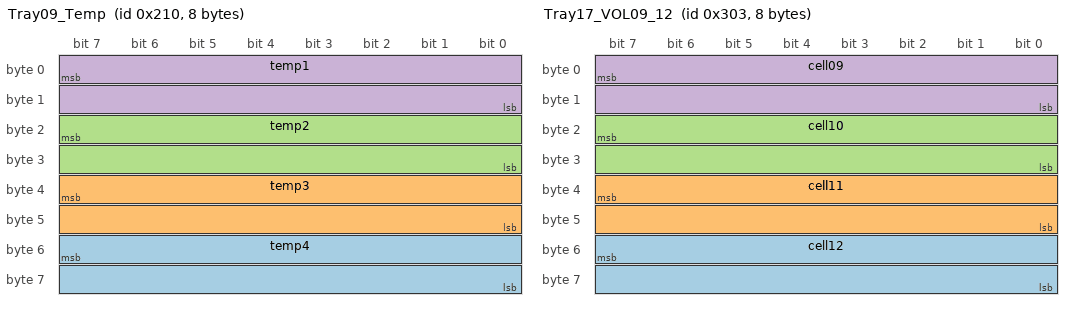
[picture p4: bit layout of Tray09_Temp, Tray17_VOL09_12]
BO_ 528 Tray09_Temp: 8 Vector__XXX
 SG_ temp4 : 55|16@0- (1,0) [0|0] "" Vector__XXX
 SG_ temp3 : 39|16@0- (1,0) [0|0] "" Vector__XXX
 SG_ temp2 : 23|16@0- (1,0) [0|0] "" Vector__XXX
 SG_ temp1 : 7|16@0- (1,0) [0|0] "" Vector__XXX

BO_ 529 Tray09_BdTemp: 4 Vector__XXX
 SG_ brdtemp2 : 23|16@0- (1,0) [0|0] "" Vector__XXX
 SG_ brdtemp1 : 7|16@0- (1,0) [0|0] "" Vector__XXX

BO_ 771 Tray17_VOL09_12: 8 Vector__XXX
 SG_ cell12 : 55|16@0+ (1,0) [0|5000] "V" Vector__XXX
 SG_ cell11 : 39|16@0+ (1,0) [0|5000] "V" Vector__XXX
 SG_ cell10 : 23|16@0+ (1,0) [0|5000] "V" Vector__XXX
 SG_ cell09 : 7|16@0+ (1,0) [0|5000] "V" Vector__XXX

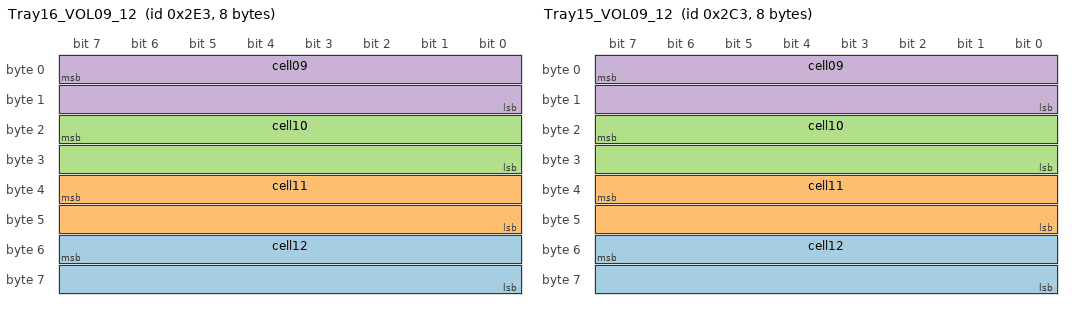
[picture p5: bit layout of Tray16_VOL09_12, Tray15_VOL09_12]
BO_ 739 Tray16_VOL09_12: 8 Vector__XXX
 SG_ cell12 : 55|16@0+ (1,0) [0|5000] "V" Vector__XXX
 SG_ cell11 : 39|16@0+ (1,0) [0|5000] "V" Vector__XXX
 SG_ cell10 : 23|16@0+ (1,0) [0|5000] "V" Vector__XXX
 SG_ cell09 : 7|16@0+ (1,0) [0|5000] "V" Vector__XXX

BO_ 707 Tray15_VOL09_12: 8 Vector__XXX
 SG_ cell12 : 55|16@0+ (1,0) [0|5000] "V" Vector__XXX
 SG_ cell11 : 39|16@0+ (1,0) [0|5000] "V" Vector__XXX
 SG_ cell10 : 23|16@0+ (1,0) [0|5000] "V" Vector__XXX
 SG_ cell09 : 7|16@0+ (1,0) [0|5000] "V" Vector__XXX

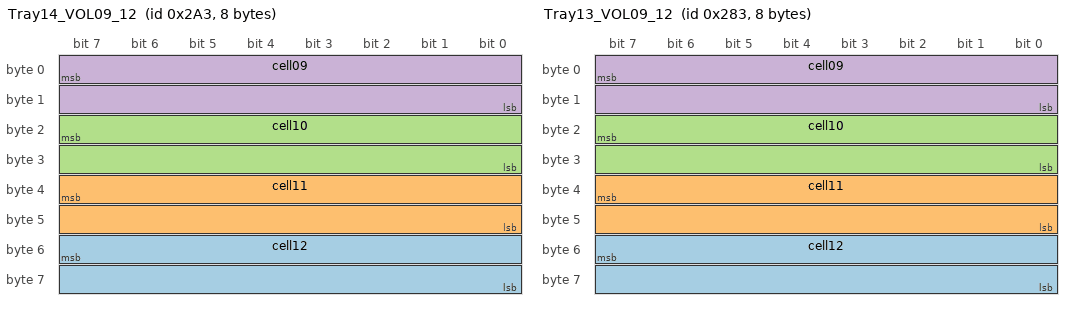
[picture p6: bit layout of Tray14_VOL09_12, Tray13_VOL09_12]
BO_ 675 Tray14_VOL09_12: 8 Vector__XXX
 SG_ cell12 : 55|16@0+ (1,0) [0|5000] "V" Vector__XXX
 SG_ cell11 : 39|16@0+ (1,0) [0|5000] "V" Vector__XXX
 SG_ cell10 : 23|16@0+ (1,0) [0|5000] "V" Vector__XXX
 SG_ cell09 : 7|16@0+ (1,0) [0|5000] "V" Vector__XXX

BO_ 643 Tray13_VOL09_12: 8 Vector__XXX
 SG_ cell12 : 55|16@0+ (1,0) [0|5000] "V" Vector__XXX
 SG_ cell11 : 39|16@0+ (1,0) [0|5000] "V" Vector__XXX
 SG_ cell10 : 23|16@0+ (1,0) [0|5000] "V" Vector__XXX
 SG_ cell09 : 7|16@0+ (1,0) [0|5000] "V" Vector__XXX

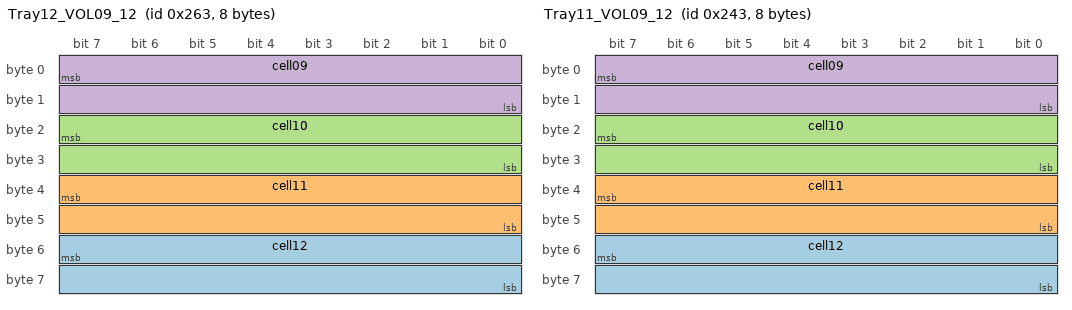
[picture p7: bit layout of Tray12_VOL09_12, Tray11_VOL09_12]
BO_ 611 Tray12_VOL09_12: 8 Vector__XXX
 SG_ cell12 : 55|16@0+ (1,0) [0|5000] "V" Vector__XXX
 SG_ cell11 : 39|16@0+ (1,0) [0|5000] "V" Vector__XXX
 SG_ cell10 : 23|16@0+ (1,0) [0|5000] "V" Vector__XXX
 SG_ cell09 : 7|16@0+ (1,0) [0|5000] "V" Vector__XXX

BO_ 579 Tray11_VOL09_12: 8 Vector__XXX
 SG_ cell12 : 55|16@0+ (1,0) [0|5000] "V" Vector__XXX
 SG_ cell11 : 39|16@0+ (1,0) [0|5000] "V" Vector__XXX
 SG_ cell10 : 23|16@0+ (1,0) [0|5000] "V" Vector__XXX
 SG_ cell09 : 7|16@0+ (1,0) [0|5000] "V" Vector__XXX

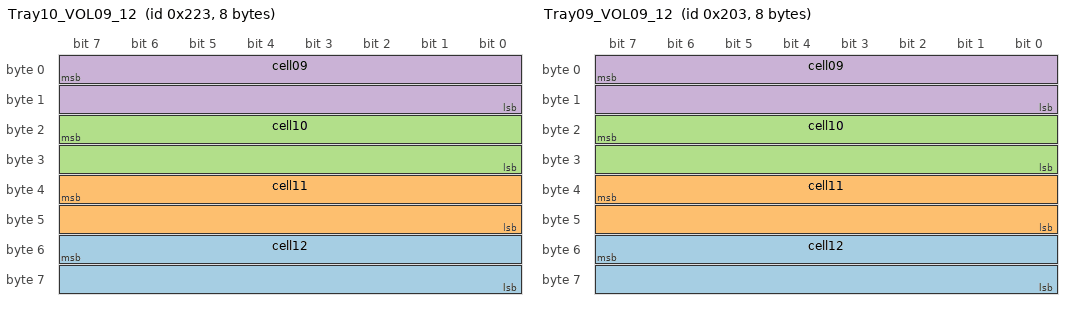
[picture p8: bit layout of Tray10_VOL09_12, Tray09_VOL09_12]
BO_ 547 Tray10_VOL09_12: 8 Vector__XXX
 SG_ cell12 : 55|16@0+ (1,0) [0|5000] "V" Vector__XXX
 SG_ cell11 : 39|16@0+ (1,0) [0|5000] "V" Vector__XXX
 SG_ cell10 : 23|16@0+ (1,0) [0|5000] "V" Vector__XXX
 SG_ cell09 : 7|16@0+ (1,0) [0|5000] "V" Vector__XXX

BO_ 515 Tray09_VOL09_12: 8 Vector__XXX
 SG_ cell12 : 55|16@0+ (1,0) [0|5000] "V" Vector__XXX
 SG_ cell11 : 39|16@0+ (1,0) [0|5000] "V" Vector__XXX
 SG_ cell10 : 23|16@0+ (1,0) [0|5000] "V" Vector__XXX
 SG_ cell09 : 7|16@0+ (1,0) [0|5000] "V" Vector__XXX

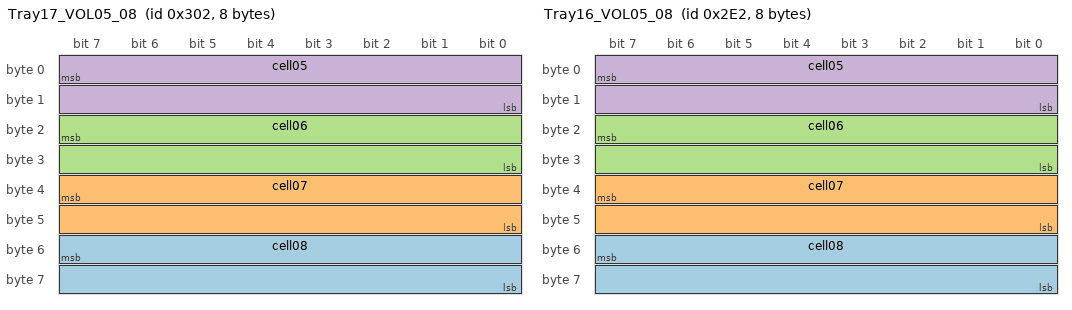
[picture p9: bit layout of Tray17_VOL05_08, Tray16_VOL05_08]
BO_ 770 Tray17_VOL05_08: 8 Vector__XXX
 SG_ cell08 : 55|16@0+ (1,0) [0|5000] "V" Vector__XXX
 SG_ cell07 : 39|16@0+ (1,0) [0|5000] "V" Vector__XXX
 SG_ cell06 : 23|16@0+ (1,0) [0|5000] "V" Vector__XXX
 SG_ cell05 : 7|16@0+ (1,0) [0|5000] "V" Vector__XXX

BO_ 738 Tray16_VOL05_08: 8 Vector__XXX
 SG_ cell08 : 55|16@0+ (1,0) [0|5000] "V" Vector__XXX
 SG_ cell07 : 39|16@0+ (1,0) [0|5000] "V" Vector__XXX
 SG_ cell06 : 23|16@0+ (1,0) [0|5000] "V" Vector__XXX
 SG_ cell05 : 7|16@0+ (1,0) [0|5000] "V" Vector__XXX

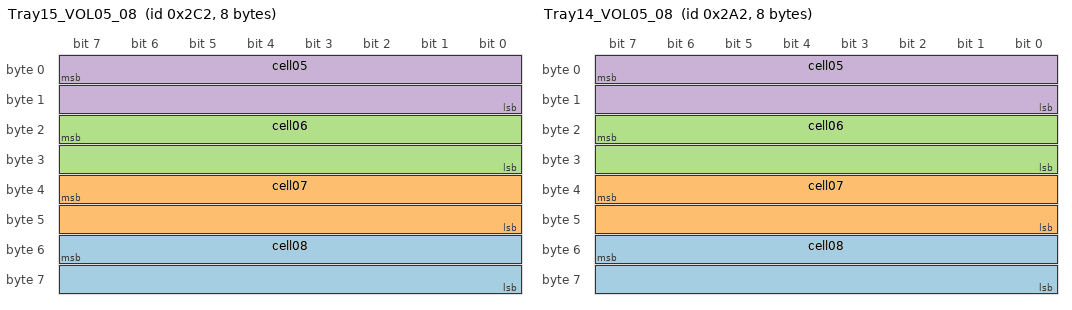
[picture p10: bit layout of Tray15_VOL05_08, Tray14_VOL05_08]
BO_ 706 Tray15_VOL05_08: 8 Vector__XXX
 SG_ cell08 : 55|16@0+ (1,0) [0|5000] "V" Vector__XXX
 SG_ cell07 : 39|16@0+ (1,0) [0|5000] "V" Vector__XXX
 SG_ cell06 : 23|16@0+ (1,0) [0|5000] "V" Vector__XXX
 SG_ cell05 : 7|16@0+ (1,0) [0|5000] "V" Vector__XXX

BO_ 674 Tray14_VOL05_08: 8 Vector__XXX
 SG_ cell08 : 55|16@0+ (1,0) [0|5000] "V" Vector__XXX
 SG_ cell07 : 39|16@0+ (1,0) [0|5000] "V" Vector__XXX
 SG_ cell06 : 23|16@0+ (1,0) [0|5000] "V" Vector__XXX
 SG_ cell05 : 7|16@0+ (1,0) [0|5000] "V" Vector__XXX

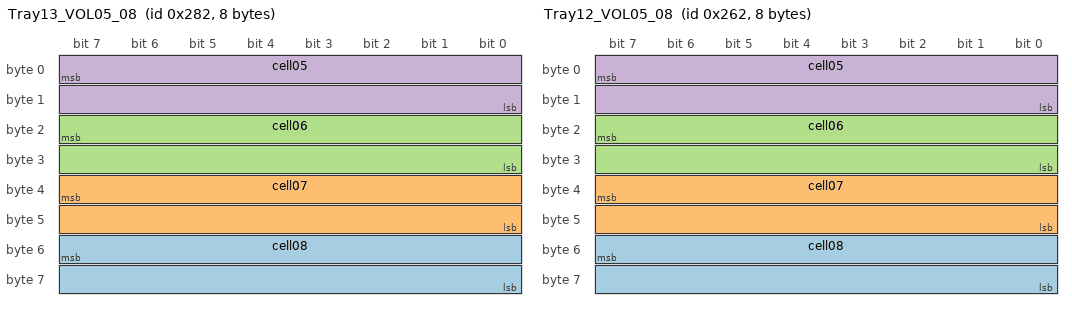
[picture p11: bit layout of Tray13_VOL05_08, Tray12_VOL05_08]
BO_ 642 Tray13_VOL05_08: 8 Vector__XXX
 SG_ cell08 : 55|16@0+ (1,0) [0|5000] "V" Vector__XXX
 SG_ cell07 : 39|16@0+ (1,0) [0|5000] "V" Vector__XXX
 SG_ cell06 : 23|16@0+ (1,0) [0|5000] "V" Vector__XXX
 SG_ cell05 : 7|16@0+ (1,0) [0|5000] "V" Vector__XXX

BO_ 610 Tray12_VOL05_08: 8 Vector__XXX
 SG_ cell08 : 55|16@0+ (1,0) [0|5000] "V" Vector__XXX
 SG_ cell07 : 39|16@0+ (1,0) [0|5000] "V" Vector__XXX
 SG_ cell06 : 23|16@0+ (1,0) [0|5000] "V" Vector__XXX
 SG_ cell05 : 7|16@0+ (1,0) [0|5000] "V" Vector__XXX

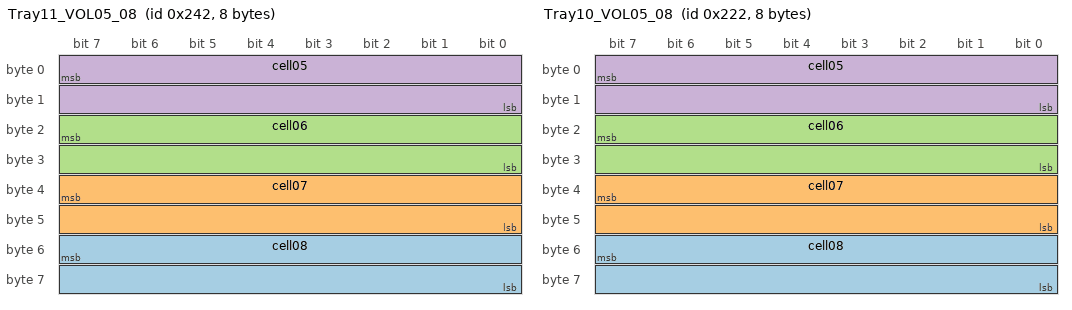
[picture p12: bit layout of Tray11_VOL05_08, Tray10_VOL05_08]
BO_ 578 Tray11_VOL05_08: 8 Vector__XXX
 SG_ cell08 : 55|16@0+ (1,0) [0|5000] "V" Vector__XXX
 SG_ cell07 : 39|16@0+ (1,0) [0|5000] "V" Vector__XXX
 SG_ cell06 : 23|16@0+ (1,0) [0|5000] "V" Vector__XXX
 SG_ cell05 : 7|16@0+ (1,0) [0|5000] "V" Vector__XXX

BO_ 546 Tray10_VOL05_08: 8 Vector__XXX
 SG_ cell08 : 55|16@0+ (1,0) [0|5000] "V" Vector__XXX
 SG_ cell07 : 39|16@0+ (1,0) [0|5000] "V" Vector__XXX
 SG_ cell06 : 23|16@0+ (1,0) [0|5000] "V" Vector__XXX
 SG_ cell05 : 7|16@0+ (1,0) [0|5000] "V" Vector__XXX

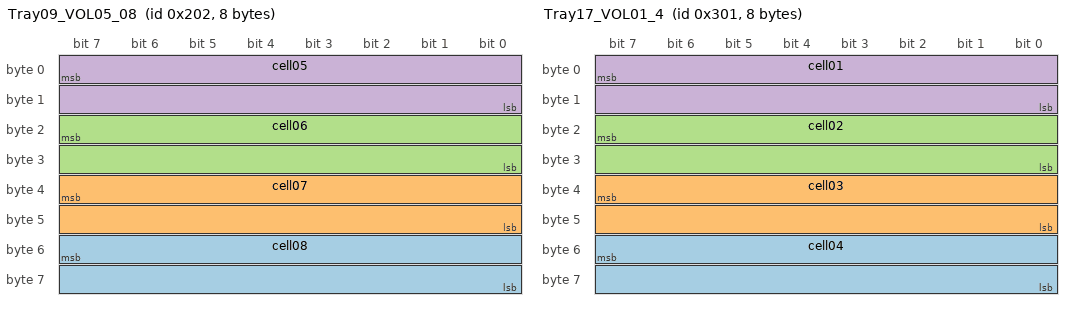
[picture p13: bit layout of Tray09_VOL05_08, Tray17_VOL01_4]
BO_ 514 Tray09_VOL05_08: 8 Vector__XXX
 SG_ cell08 : 55|16@0+ (1,0) [0|5000] "V" Vector__XXX
 SG_ cell07 : 39|16@0+ (1,0) [0|5000] "V" Vector__XXX
 SG_ cell06 : 23|16@0+ (1,0) [0|5000] "V" Vector__XXX
 SG_ cell05 : 7|16@0+ (1,0) [0|5000] "V" Vector__XXX

BO_ 769 Tray17_VOL01_4: 8 Vector__XXX
 SG_ cell04 : 55|16@0+ (1,0) [0|5000] "V" Vector__XXX
 SG_ cell03 : 39|16@0+ (1,0) [0|5000] "V" Vector__XXX
 SG_ cell02 : 23|16@0+ (1,0) [0|5000] "V" Vector__XXX
 SG_ cell01 : 7|16@0+ (1,0) [0|5000] "V" Vector__XXX

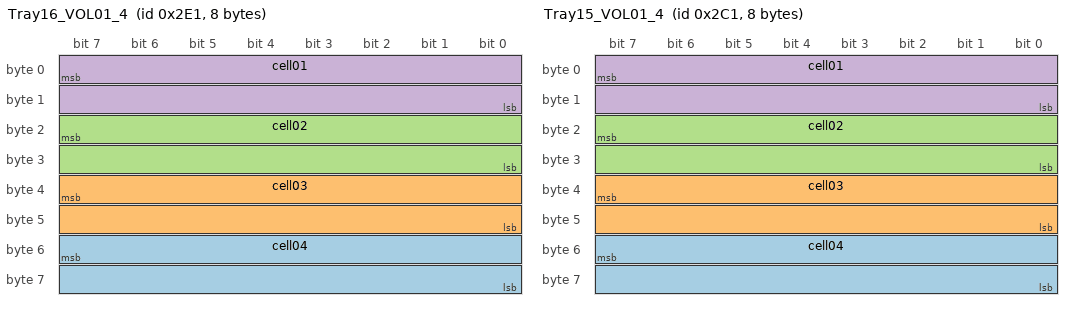
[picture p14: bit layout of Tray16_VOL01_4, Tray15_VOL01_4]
BO_ 737 Tray16_VOL01_4: 8 Vector__XXX
 SG_ cell04 : 55|16@0+ (1,0) [0|5000] "V" Vector__XXX
 SG_ cell03 : 39|16@0+ (1,0) [0|5000] "V" Vector__XXX
 SG_ cell02 : 23|16@0+ (1,0) [0|5000] "V" Vector__XXX
 SG_ cell01 : 7|16@0+ (1,0) [0|5000] "V" Vector__XXX

BO_ 705 Tray15_VOL01_4: 8 Vector__XXX
 SG_ cell04 : 55|16@0+ (1,0) [0|5000] "V" Vector__XXX
 SG_ cell03 : 39|16@0+ (1,0) [0|5000] "V" Vector__XXX
 SG_ cell02 : 23|16@0+ (1,0) [0|5000] "V" Vector__XXX
 SG_ cell01 : 7|16@0+ (1,0) [0|5000] "V" Vector__XXX

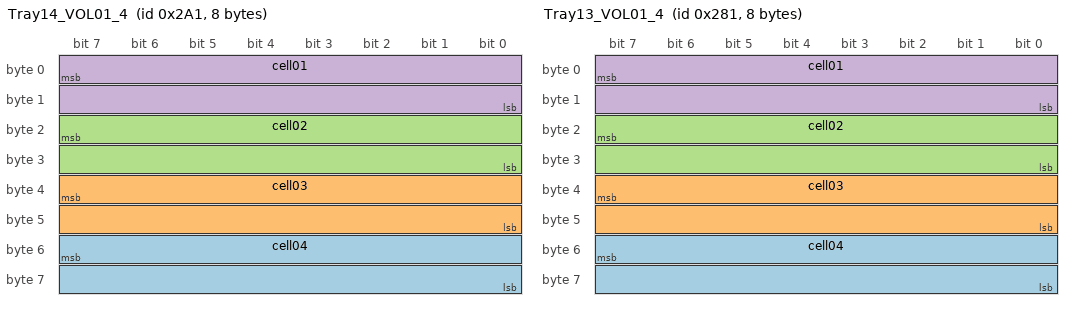
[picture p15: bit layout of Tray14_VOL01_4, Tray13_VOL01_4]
BO_ 673 Tray14_VOL01_4: 8 Vector__XXX
 SG_ cell04 : 55|16@0+ (1,0) [0|5000] "V" Vector__XXX
 SG_ cell03 : 39|16@0+ (1,0) [0|5000] "V" Vector__XXX
 SG_ cell02 : 23|16@0+ (1,0) [0|5000] "V" Vector__XXX
 SG_ cell01 : 7|16@0+ (1,0) [0|5000] "V" Vector__XXX

BO_ 641 Tray13_VOL01_4: 8 Vector__XXX
 SG_ cell04 : 55|16@0+ (1,0) [0|5000] "V" Vector__XXX
 SG_ cell03 : 39|16@0+ (1,0) [0|5000] "V" Vector__XXX
 SG_ cell02 : 23|16@0+ (1,0) [0|5000] "V" Vector__XXX
 SG_ cell01 : 7|16@0+ (1,0) [0|5000] "V" Vector__XXX

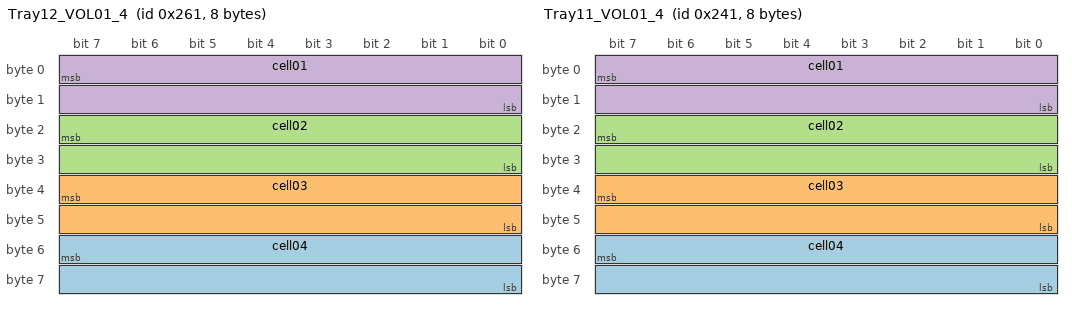
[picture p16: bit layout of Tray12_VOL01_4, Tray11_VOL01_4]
BO_ 609 Tray12_VOL01_4: 8 Vector__XXX
 SG_ cell04 : 55|16@0+ (1,0) [0|5000] "V" Vector__XXX
 SG_ cell03 : 39|16@0+ (1,0) [0|5000] "V" Vector__XXX
 SG_ cell02 : 23|16@0+ (1,0) [0|5000] "V" Vector__XXX
 SG_ cell01 : 7|16@0+ (1,0) [0|5000] "V" Vector__XXX

BO_ 577 Tray11_VOL01_4: 8 Vector__XXX
 SG_ cell04 : 55|16@0+ (1,0) [0|5000] "V" Vector__XXX
 SG_ cell03 : 39|16@0+ (1,0) [0|5000] "V" Vector__XXX
 SG_ cell02 : 23|16@0+ (1,0) [0|5000] "V" Vector__XXX
 SG_ cell01 : 7|16@0+ (1,0) [0|5000] "V" Vector__XXX

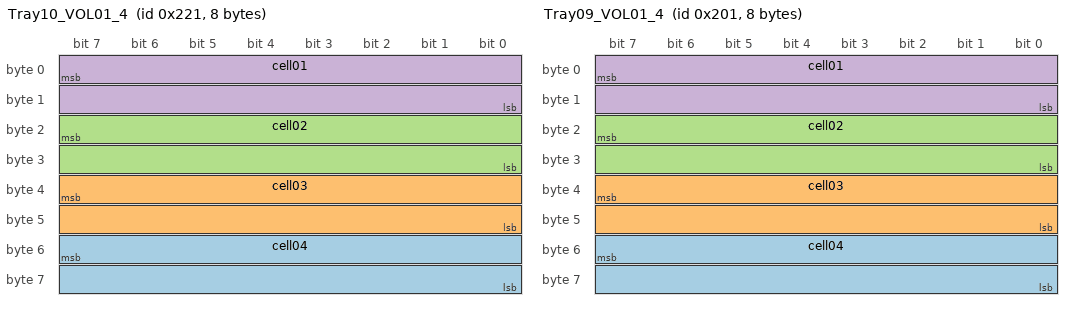
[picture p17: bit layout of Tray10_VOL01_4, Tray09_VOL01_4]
BO_ 545 Tray10_VOL01_4: 8 Vector__XXX
 SG_ cell04 : 55|16@0+ (1,0) [0|5000] "V" Vector__XXX
 SG_ cell03 : 39|16@0+ (1,0) [0|5000] "V" Vector__XXX
 SG_ cell02 : 23|16@0+ (1,0) [0|5000] "V" Vector__XXX
 SG_ cell01 : 7|16@0+ (1,0) [0|5000] "V" Vector__XXX

BO_ 513 Tray09_VOL01_4: 8 Vector__XXX
 SG_ cell04 : 55|16@0+ (1,0) [0|5000] "V" Vector__XXX
 SG_ cell03 : 39|16@0+ (1,0) [0|5000] "V" Vector__XXX
 SG_ cell02 : 23|16@0+ (1,0) [0|5000] "V" Vector__XXX
 SG_ cell01 : 7|16@0+ (1,0) [0|5000] "V" Vector__XXX

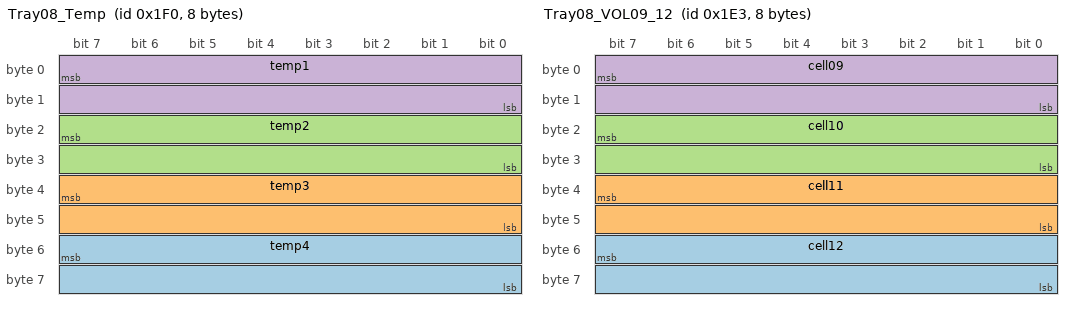
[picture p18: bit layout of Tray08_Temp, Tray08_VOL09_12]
BO_ 496 Tray08_Temp: 8 Vector__XXX
 SG_ temp4 : 55|16@0- (1,0) [0|0] "" Vector__XXX
 SG_ temp3 : 39|16@0- (1,0) [0|0] "" Vector__XXX
 SG_ temp2 : 23|16@0- (1,0) [0|0] "" Vector__XXX
 SG_ temp1 : 7|16@0- (1,0) [0|0] "" Vector__XXX

BO_ 497 Tray08_BdTemp: 4 Vector__XXX
 SG_ brdtemp2 : 23|16@0- (1,0) [0|0] "" Vector__XXX
 SG_ brdtemp1 : 7|16@0- (1,0) [0|0] "" Vector__XXX

BO_ 483 Tray08_VOL09_12: 8 Vector__XXX
 SG_ cell12 : 55|16@0+ (1,0) [0|5000] "V" Vector__XXX
 SG_ cell11 : 39|16@0+ (1,0) [0|5000] "V" Vector__XXX
 SG_ cell10 : 23|16@0+ (1,0) [0|5000] "V" Vector__XXX
 SG_ cell09 : 7|16@0+ (1,0) [0|5000] "V" Vector__XXX

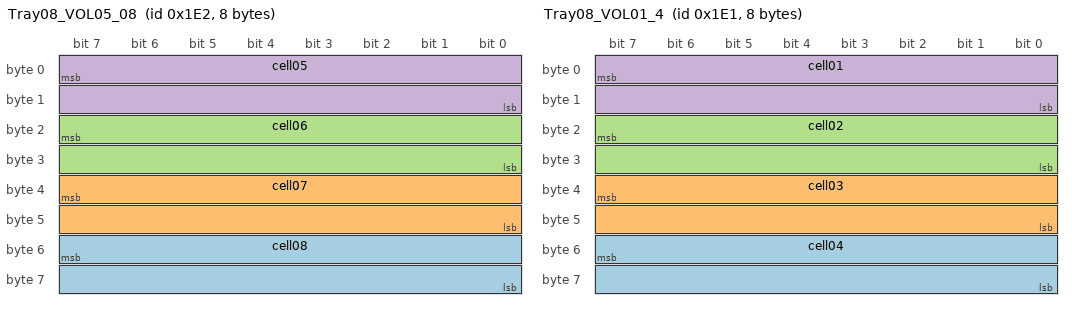
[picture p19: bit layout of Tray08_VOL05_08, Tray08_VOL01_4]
BO_ 482 Tray08_VOL05_08: 8 Vector__XXX
 SG_ cell08 : 55|16@0+ (1,0) [0|5000] "V" Vector__XXX
 SG_ cell07 : 39|16@0+ (1,0) [0|5000] "V" Vector__XXX
 SG_ cell06 : 23|16@0+ (1,0) [0|5000] "V" Vector__XXX
 SG_ cell05 : 7|16@0+ (1,0) [0|5000] "V" Vector__XXX

BO_ 481 Tray08_VOL01_4: 8 Vector__XXX
 SG_ cell04 : 55|16@0+ (1,0) [0|5000] "V" Vector__XXX
 SG_ cell03 : 39|16@0+ (1,0) [0|5000] "V" Vector__XXX
 SG_ cell02 : 23|16@0+ (1,0) [0|5000] "V" Vector__XXX
 SG_ cell01 : 7|16@0+ (1,0) [0|5000] "V" Vector__XXX

BO_ 464 Tray07_Temp: 8 Vector__XXX
 SG_ temp4 : 55|16@0- (1,0) [0|0] "" Vector__XXX
 SG_ temp3 : 39|16@0- (1,0) [0|0] "" Vector__XXX
 SG_ temp2 : 23|16@0- (1,0) [0|0] "" Vector__XXX
 SG_ temp1 : 7|16@0- (1,0) [0|0] "" Vector__XXX

BO_ 465 Tray07_BdTemp: 4 Vector__XXX
 SG_ brdtemp2 : 23|16@0- (1,0) [0|0] "" Vector__XXX
 SG_ brdtemp1 : 7|16@0- (1,0) [0|0] "" Vector__XXX

BO_ 451 Tray07_VOL09_12: 8 Vector__XXX
 SG_ cell12 : 55|16@0+ (1,0) [0|5000] "V" Vector__XXX
 SG_ cell11 : 39|16@0+ (1,0) [0|5000] "V" Vector__XXX
 SG_ cell10 : 23|16@0+ (1,0) [0|5000] "V" Vector__XXX
 SG_ cell09 : 7|16@0+ (1,0) [0|5000] "V" Vector__XXX

BO_ 450 Tray07_VOL05_08: 8 Vector__XXX
 SG_ cell08 : 55|16@0+ (1,0) [0|5000] "V" Vector__XXX
 SG_ cell07 : 39|16@0+ (1,0) [0|5000] "V" Vector__XXX
 SG_ cell06 : 23|16@0+ (1,0) [0|5000] "V" Vector__XXX
 SG_ cell05 : 7|16@0+ (1,0) [0|5000] "V" Vector__XXX

BO_ 449 Tray07_VOL01_4: 8 Vector__XXX
 SG_ cell04 : 55|16@0+ (1,0) [0|5000] "V" Vector__XXX
 SG_ cell03 : 39|16@0+ (1,0) [0|5000] "V" Vector__XXX
 SG_ cell02 : 23|16@0+ (1,0) [0|5000] "V" Vector__XXX
 SG_ cell01 : 7|16@0+ (1,0) [0|5000] "V" Vector__XXX

BO_ 427 Tray06_VOL41_44: 8 Vector__XXX
 SG_ cell44 : 55|16@0+ (1,0) [0|5000] "V" Vector__XXX
 SG_ cell43 : 39|16@0+ (1,0) [0|5000] "V" Vector__XXX
 SG_ cell42 : 23|16@0+ (1,0) [0|5000] "V" Vector__XXX
 SG_ cell41 : 7|16@0+ (1,0) [0|5000] "V" Vector__XXX

BO_ 395 Tray05_VOL41_44: 8 Vector__XXX
 SG_ cell44 : 55|16@0+ (1,0) [0|5000] "V" Vector__XXX
 SG_ cell43 : 39|16@0+ (1,0) [0|5000] "V" Vector__XXX
 SG_ cell42 : 23|16@0+ (1,0) [0|5000] "V" Vector__XXX
 SG_ cell41 : 7|16@0+ (1,0) [0|5000] "V" Vector__XXX

BO_ 363 Tray04_VOL41_44: 8 Vector__XXX
 SG_ cell44 : 55|16@0+ (1,0) [0|5000] "V" Vector__XXX
 SG_ cell43 : 39|16@0+ (1,0) [0|5000] "V" Vector__XXX
 SG_ cell42 : 23|16@0+ (1,0) [0|5000] "V" Vector__XXX
 SG_ cell41 : 7|16@0+ (1,0) [0|5000] "V" Vector__XXX

BO_ 331 Tray03_VOL41_44: 8 Vector__XXX
 SG_ cell44 : 55|16@0+ (1,0) [0|5000] "V" Vector__XXX
 SG_ cell43 : 39|16@0+ (1,0) [0|5000] "V" Vector__XXX
 SG_ cell42 : 23|16@0+ (1,0) [0|5000] "V" Vector__XXX
 SG_ cell41 : 7|16@0+ (1,0) [0|5000] "V" Vector__XXX

BO_ 432 Tray06_Temp: 8 Vector__XXX
 SG_ temp4 : 55|16@0- (1,0) [0|0] "" Vector__XXX
 SG_ temp3 : 39|16@0- (1,0) [0|0] "" Vector__XXX
 SG_ temp2 : 23|16@0- (1,0) [0|0] "" Vector__XXX
 SG_ temp1 : 7|16@0- (1,0) [0|0] "" Vector__XXX

BO_ 400 Tray05_Temp: 8 Vector__XXX
 SG_ temp4 : 55|16@0- (1,0) [0|0] "" Vector__XXX
 SG_ temp3 : 39|16@0- (1,0) [0|0] "" Vector__XXX
 SG_ temp2 : 23|16@0- (1,0) [0|0] "" Vector__XXX
 SG_ temp1 : 7|16@0- (1,0) [0|0] "" Vector__XXX

BO_ 368 Tray04_Temp: 8 Vector__XXX
 SG_ temp4 : 55|16@0- (1,0) [0|0] "" Vector__XXX
 SG_ temp3 : 39|16@0- (1,0) [0|0] "" Vector__XXX
 SG_ temp2 : 23|16@0- (1,0) [0|0] "" Vector__XXX
 SG_ temp1 : 7|16@0- (1,0) [0|0] "" Vector__XXX

BO_ 336 Tray03_Temp: 8 Vector__XXX
 SG_ temp4 : 55|16@0- (1,0) [0|0] "" Vector__XXX
 SG_ temp3 : 39|16@0- (1,0) [0|0] "" Vector__XXX
 SG_ temp2 : 23|16@0- (1,0) [0|0] "" Vector__XXX
 SG_ temp1 : 7|16@0- (1,0) [0|0] "" Vector__XXX

BO_ 304 Tray02_Temp: 8 Vector__XXX
 SG_ temp4 : 55|16@0- (1,0) [0|0] "" Vector__XXX
 SG_ temp3 : 39|16@0- (1,0) [0|0] "" Vector__XXX
 SG_ temp2 : 23|16@0- (1,0) [0|0] "" Vector__XXX
 SG_ temp1 : 7|16@0- (1,0) [0|0] "" Vector__XXX

BO_ 433 Tray06_BdTemp: 4 Vector__XXX
 SG_ brdtemp2 : 23|16@0- (1,0) [0|0] "" Vector__XXX
 SG_ brdtemp1 : 7|16@0- (1,0) [0|0] "" Vector__XXX

BO_ 401 Tray05_BdTemp: 4 Vector__XXX
 SG_ brdtemp2 : 23|16@0- (1,0) [0|0] "" Vector__XXX
 SG_ brdtemp1 : 7|16@0- (1,0) [0|0] "" Vector__XXX

BO_ 369 Tray04_BdTemp: 4 Vector__XXX
 SG_ brdtemp2 : 23|16@0- (1,0) [0|0] "" Vector__XXX
 SG_ brdtemp1 : 7|16@0- (1,0) [0|0] "" Vector__XXX

BO_ 337 Tray03_BdTemp: 4 Vector__XXX
 SG_ brdtemp2 : 23|16@0- (1,0) [0|0] "" Vector__XXX
 SG_ brdtemp1 : 7|16@0- (1,0) [0|0] "" Vector__XXX

BO_ 305 Tray02_BdTemp: 4 Vector__XXX
 SG_ brdtemp2 : 23|16@0- (1,0) [0|0] "" Vector__XXX
 SG_ brdtemp1 : 7|16@0- (1,0) [0|0] "" Vector__XXX

BO_ 396 Tray05_VOL45_48: 4 Vector__XXX
 SG_ cell46 : 23|16@0+ (1,0) [0|5000] "V" Vector__XXX
 SG_ cell45 : 7|16@0+ (1,0) [0|5000] "V" Vector__XXX

BO_ 428 Tray06_VOL45_48: 4 Vector__XXX
 SG_ cell46 : 23|16@0+ (1,0) [0|5000] "V" Vector__XXX
 SG_ cell45 : 7|16@0+ (1,0) [0|5000] "V" Vector__XXX

BO_ 364 Tray04_VOL45_48: 4 Vector__XXX
 SG_ cell46 : 23|16@0+ (1,0) [0|5000] "V" Vector__XXX
 SG_ cell45 : 7|16@0+ (1,0) [0|5000] "V" Vector__XXX

BO_ 332 Tray03_VOL45_48: 4 Vector__XXX
 SG_ cell46 : 23|16@0+ (1,0) [0|5000] "V" Vector__XXX
 SG_ cell45 : 7|16@0+ (1,0) [0|5000] "V" Vector__XXX

BO_ 426 Tray06_VOL37_40: 8 Vector__XXX
 SG_ cell40 : 55|16@0+ (1,0) [0|5000] "V" Vector__XXX
 SG_ cell39 : 39|16@0+ (1,0) [0|5000] "V" Vector__XXX
 SG_ cell38 : 23|16@0+ (1,0) [0|5000] "V" Vector__XXX
 SG_ cell37 : 7|16@0+ (1,0) [0|5000] "V" Vector__XXX

BO_ 394 Tray05_VOL37_40: 8 Vector__XXX
 SG_ cell40 : 55|16@0+ (1,0) [0|5000] "V" Vector__XXX
 SG_ cell39 : 39|16@0+ (1,0) [0|5000] "V" Vector__XXX
 SG_ cell38 : 23|16@0+ (1,0) [0|5000] "V" Vector__XXX
 SG_ cell37 : 7|16@0+ (1,0) [0|5000] "V" Vector__XXX

BO_ 362 Tray04_VOL37_40: 8 Vector__XXX
 SG_ cell40 : 55|16@0+ (1,0) [0|5000] "V" Vector__XXX
 SG_ cell39 : 39|16@0+ (1,0) [0|5000] "V" Vector__XXX
 SG_ cell38 : 23|16@0+ (1,0) [0|5000] "V" Vector__XXX
 SG_ cell37 : 7|16@0+ (1,0) [0|5000] "V" Vector__XXX

BO_ 330 Tray03_VOL37_40: 8 Vector__XXX
 SG_ cell40 : 55|16@0+ (1,0) [0|5000] "V" Vector__XXX
 SG_ cell39 : 39|16@0+ (1,0) [0|5000] "V" Vector__XXX
 SG_ cell38 : 23|16@0+ (1,0) [0|5000] "V" Vector__XXX
 SG_ cell37 : 7|16@0+ (1,0) [0|5000] "V" Vector__XXX

BO_ 425 Tray06_VOL33_36: 8 Vector__XXX
 SG_ cell36 : 55|16@0+ (1,0) [0|5000] "V" Vector__XXX
 SG_ cell35 : 39|16@0+ (1,0) [0|5000] "V" Vector__XXX
 SG_ cell34 : 23|16@0+ (1,0) [0|5000] "V" Vector__XXX
 SG_ cell33 : 7|16@0+ (1,0) [0|5000] "V" Vector__XXX

BO_ 393 Tray05_VOL33_36: 8 Vector__XXX
 SG_ cell36 : 55|16@0+ (1,0) [0|5000] "V" Vector__XXX
 SG_ cell35 : 39|16@0+ (1,0) [0|5000] "V" Vector__XXX
 SG_ cell34 : 23|16@0+ (1,0) [0|5000] "V" Vector__XXX
 SG_ cell33 : 7|16@0+ (1,0) [0|5000] "V" Vector__XXX

BO_ 361 Tray04_VOL33_36: 8 Vector__XXX
 SG_ cell36 : 55|16@0+ (1,0) [0|5000] "V" Vector__XXX
 SG_ cell35 : 39|16@0+ (1,0) [0|5000] "V" Vector__XXX
 SG_ cell34 : 23|16@0+ (1,0) [0|5000] "V" Vector__XXX
 SG_ cell33 : 7|16@0+ (1,0) [0|5000] "V" Vector__XXX

BO_ 329 Tray03_VOL33_36: 8 Vector__XXX
 SG_ cell36 : 55|16@0+ (1,0) [0|5000] "V" Vector__XXX
 SG_ cell35 : 39|16@0+ (1,0) [0|5000] "V" Vector__XXX
 SG_ cell34 : 23|16@0+ (1,0) [0|5000] "V" Vector__XXX
 SG_ cell33 : 7|16@0+ (1,0) [0|5000] "V" Vector__XXX

BO_ 424 Tray06_VOL29_32: 8 Vector__XXX
 SG_ cell32 : 55|16@0+ (1,0) [0|5000] "V" Vector__XXX
 SG_ cell31 : 39|16@0+ (1,0) [0|5000] "V" Vector__XXX
 SG_ cell30 : 23|16@0+ (1,0) [0|5000] "V" Vector__XXX
 SG_ cell29 : 7|16@0+ (1,0) [0|5000] "V" Vector__XXX

BO_ 392 Tray05_VOL29_32: 8 Vector__XXX
 SG_ cell32 : 55|16@0+ (1,0) [0|5000] "V" Vector__XXX
 SG_ cell31 : 39|16@0+ (1,0) [0|5000] "V" Vector__XXX
 SG_ cell30 : 23|16@0+ (1,0) [0|5000] "V" Vector__XXX
 SG_ cell29 : 7|16@0+ (1,0) [0|5000] "V" Vector__XXX

BO_ 360 Tray04_VOL29_32: 8 Vector__XXX
 SG_ cell32 : 55|16@0+ (1,0) [0|5000] "V" Vector__XXX
 SG_ cell31 : 39|16@0+ (1,0) [0|5000] "V" Vector__XXX
 SG_ cell30 : 23|16@0+ (1,0) [0|5000] "V" Vector__XXX
 SG_ cell29 : 7|16@0+ (1,0) [0|5000] "V" Vector__XXX

BO_ 328 Tray03_VOL29_32: 8 Vector__XXX
 SG_ cell32 : 55|16@0+ (1,0) [0|5000] "V" Vector__XXX
 SG_ cell31 : 39|16@0+ (1,0) [0|5000] "V" Vector__XXX
 SG_ cell30 : 23|16@0+ (1,0) [0|5000] "V" Vector__XXX
 SG_ cell29 : 7|16@0+ (1,0) [0|5000] "V" Vector__XXX

BO_ 423 Tray06_VOL25_28: 8 Vector__XXX
 SG_ cell28 : 55|16@0+ (1,0) [0|5000] "V" Vector__XXX
 SG_ cell27 : 39|16@0+ (1,0) [0|5000] "V" Vector__XXX
 SG_ cell26 : 23|16@0+ (1,0) [0|5000] "V" Vector__XXX
 SG_ cell25 : 7|16@0+ (1,0) [0|5000] "V" Vector__XXX

BO_ 391 Tray05_VOL25_28: 8 Vector__XXX
 SG_ cell28 : 55|16@0+ (1,0) [0|5000] "V" Vector__XXX
 SG_ cell27 : 39|16@0+ (1,0) [0|5000] "V" Vector__XXX
 SG_ cell26 : 23|16@0+ (1,0) [0|5000] "V" Vector__XXX
 SG_ cell25 : 7|16@0+ (1,0) [0|5000] "V" Vector__XXX

BO_ 359 Tray04_VOL25_28: 8 Vector__XXX
 SG_ cell28 : 55|16@0+ (1,0) [0|5000] "V" Vector__XXX
 SG_ cell27 : 39|16@0+ (1,0) [0|5000] "V" Vector__XXX
 SG_ cell26 : 23|16@0+ (1,0) [0|5000] "V" Vector__XXX
 SG_ cell25 : 7|16@0+ (1,0) [0|5000] "V" Vector__XXX

BO_ 327 Tray03_VOL25_28: 8 Vector__XXX
 SG_ cell28 : 55|16@0+ (1,0) [0|5000] "V" Vector__XXX
 SG_ cell27 : 39|16@0+ (1,0) [0|5000] "V" Vector__XXX
 SG_ cell26 : 23|16@0+ (1,0) [0|5000] "V" Vector__XXX
 SG_ cell25 : 7|16@0+ (1,0) [0|5000] "V" Vector__XXX

BO_ 422 Tray06_VOL21_24: 8 Vector__XXX
 SG_ cell24 : 55|16@0+ (1,0) [0|5000] "V" Vector__XXX
 SG_ cell23 : 39|16@0+ (1,0) [0|5000] "V" Vector__XXX
 SG_ cell22 : 23|16@0+ (1,0) [0|5000] "V" Vector__XXX
 SG_ cell21 : 7|16@0+ (1,0) [0|5000] "V" Vector__XXX

BO_ 390 Tray05_VOL21_24: 8 Vector__XXX
 SG_ cell24 : 55|16@0+ (1,0) [0|5000] "V" Vector__XXX
 SG_ cell23 : 39|16@0+ (1,0) [0|5000] "V" Vector__XXX
 SG_ cell22 : 23|16@0+ (1,0) [0|5000] "V" Vector__XXX
 SG_ cell21 : 7|16@0+ (1,0) [0|5000] "V" Vector__XXX

BO_ 358 Tray04_VOL21_24: 8 Vector__XXX
 SG_ cell24 : 55|16@0+ (1,0) [0|5000] "V" Vector__XXX
 SG_ cell23 : 39|16@0+ (1,0) [0|5000] "V" Vector__XXX
 SG_ cell22 : 23|16@0+ (1,0) [0|5000] "V" Vector__XXX
 SG_ cell21 : 7|16@0+ (1,0) [0|5000] "V" Vector__XXX

BO_ 326 Tray03_VOL21_24: 8 Vector__XXX
 SG_ cell24 : 55|16@0+ (1,0) [0|5000] "V" Vector__XXX
 SG_ cell23 : 39|16@0+ (1,0) [0|5000] "V" Vector__XXX
 SG_ cell22 : 23|16@0+ (1,0) [0|5000] "V" Vector__XXX
 SG_ cell21 : 7|16@0+ (1,0) [0|5000] "V" Vector__XXX

BO_ 421 Tray06_VOL17_20: 8 Vector__XXX
 SG_ cell20 : 55|16@0+ (1,0) [0|5000] "V" Vector__XXX
 SG_ cell19 : 39|16@0+ (1,0) [0|5000] "V" Vector__XXX
 SG_ cell18 : 23|16@0+ (1,0) [0|5000] "V" Vector__XXX
 SG_ cell17 : 7|16@0+ (1,0) [0|5000] "V" Vector__XXX

BO_ 389 Tray05_VOL17_20: 8 Vector__XXX
 SG_ cell20 : 55|16@0+ (1,0) [0|5000] "V" Vector__XXX
 SG_ cell19 : 39|16@0+ (1,0) [0|5000] "V" Vector__XXX
 SG_ cell18 : 23|16@0+ (1,0) [0|5000] "V" Vector__XXX
 SG_ cell17 : 7|16@0+ (1,0) [0|5000] "V" Vector__XXX

BO_ 357 Tray04_VOL17_20: 8 Vector__XXX
 SG_ cell20 : 55|16@0+ (1,0) [0|5000] "V" Vector__XXX
 SG_ cell19 : 39|16@0+ (1,0) [0|5000] "V" Vector__XXX
 SG_ cell18 : 23|16@0+ (1,0) [0|5000] "V" Vector__XXX
 SG_ cell17 : 7|16@0+ (1,0) [0|5000] "V" Vector__XXX

BO_ 325 Tray03_VOL17_20: 8 Vector__XXX
 SG_ cell20 : 55|16@0+ (1,0) [0|5000] "V" Vector__XXX
 SG_ cell19 : 39|16@0+ (1,0) [0|5000] "V" Vector__XXX
 SG_ cell18 : 23|16@0+ (1,0) [0|5000] "V" Vector__XXX
 SG_ cell17 : 7|16@0+ (1,0) [0|5000] "V" Vector__XXX

BO_ 420 Tray06_VOL13_16_: 8 Vector__XXX
 SG_ cell16 : 55|16@0- (1,0) [0|5000] "V" Vector__XXX
 SG_ cell15 : 39|16@0+ (1,0) [0|5000] "V" Vector__XXX
 SG_ cell14 : 23|16@0+ (1,0) [0|5000] "V" Vector__XXX
 SG_ cell13 : 7|16@0+ (1,0) [0|5000] "V" Vector__XXX

BO_ 388 Tray05_VOL13_16: 8 Vector__XXX
 SG_ cell16 : 55|16@0- (1,0) [0|5000] "V" Vector__XXX
 SG_ cell15 : 39|16@0+ (1,0) [0|5000] "V" Vector__XXX
 SG_ cell14 : 23|16@0+ (1,0) [0|5000] "V" Vector__XXX
 SG_ cell13 : 7|16@0+ (1,0) [0|5000] "V" Vector__XXX

BO_ 356 Tray04_VOL13_16: 8 Vector__XXX
 SG_ cell16 : 55|16@0- (1,0) [0|5000] "V" Vector__XXX
 SG_ cell15 : 39|16@0+ (1,0) [0|5000] "V" Vector__XXX
 SG_ cell14 : 23|16@0+ (1,0) [0|5000] "V" Vector__XXX
 SG_ cell13 : 7|16@0+ (1,0) [0|5000] "V" Vector__XXX

BO_ 324 Tray03_VOL13_16: 8 Vector__XXX
 SG_ cell16 : 55|16@0- (1,0) [0|5000] "V" Vector__XXX
 SG_ cell15 : 39|16@0+ (1,0) [0|5000] "V" Vector__XXX
 SG_ cell14 : 23|16@0+ (1,0) [0|5000] "V" Vector__XXX
 SG_ cell13 : 7|16@0+ (1,0) [0|5000] "V" Vector__XXX

BO_ 419 Tray06_VOL09_12: 8 Vector__XXX
 SG_ cell12 : 55|16@0+ (1,0) [0|5000] "V" Vector__XXX
 SG_ cell11 : 39|16@0+ (1,0) [0|5000] "V" Vector__XXX
 SG_ cell10 : 23|16@0+ (1,0) [0|5000] "V" Vector__XXX
 SG_ cell09 : 7|16@0+ (1,0) [0|5000] "V" Vector__XXX

BO_ 387 Tray05_VOL09_12: 8 Vector__XXX
 SG_ cell12 : 55|16@0+ (1,0) [0|5000] "V" Vector__XXX
 SG_ cell11 : 39|16@0+ (1,0) [0|5000] "V" Vector__XXX
 SG_ cell10 : 23|16@0+ (1,0) [0|5000] "V" Vector__XXX
 SG_ cell09 : 7|16@0+ (1,0) [0|5000] "V" Vector__XXX

BO_ 355 Tray04_VOL09_12: 8 Vector__XXX
 SG_ cell12 : 55|16@0+ (1,0) [0|5000] "V" Vector__XXX
 SG_ cell11 : 39|16@0+ (1,0) [0|5000] "V" Vector__XXX
 SG_ cell10 : 23|16@0+ (1,0) [0|5000] "V" Vector__XXX
 SG_ cell09 : 7|16@0+ (1,0) [0|5000] "V" Vector__XXX

BO_ 323 Tray03_VOL09_12: 8 Vector__XXX
 SG_ cell12 : 55|16@0+ (1,0) [0|5000] "V" Vector__XXX
 SG_ cell11 : 39|16@0+ (1,0) [0|5000] "V" Vector__XXX
 SG_ cell10 : 23|16@0+ (1,0) [0|5000] "V" Vector__XXX
 SG_ cell09 : 7|16@0+ (1,0) [0|5000] "V" Vector__XXX

BO_ 418 Tray06_VOL05_08: 8 Vector__XXX
 SG_ cell08 : 55|16@0+ (1,0) [0|5000] "V" Vector__XXX
 SG_ cell07 : 39|16@0+ (1,0) [0|5000] "V" Vector__XXX
 SG_ cell06 : 23|16@0+ (1,0) [0|5000] "V" Vector__XXX
 SG_ cell05 : 7|16@0+ (1,0) [0|5000] "V" Vector__XXX

BO_ 386 Tray05_VOL05_08: 8 Vector__XXX
 SG_ cell08 : 55|16@0+ (1,0) [0|5000] "V" Vector__XXX
 SG_ cell07 : 39|16@0+ (1,0) [0|5000] "V" Vector__XXX
 SG_ cell06 : 23|16@0+ (1,0) [0|5000] "V" Vector__XXX
 SG_ cell05 : 7|16@0+ (1,0) [0|5000] "V" Vector__XXX

BO_ 354 Tray04_VOL05_08: 8 Vector__XXX
 SG_ cell08 : 55|16@0+ (1,0) [0|5000] "V" Vector__XXX
 SG_ cell07 : 39|16@0+ (1,0) [0|5000] "V" Vector__XXX
 SG_ cell06 : 23|16@0+ (1,0) [0|5000] "V" Vector__XXX
 SG_ cell05 : 7|16@0+ (1,0) [0|5000] "V" Vector__XXX

BO_ 322 Tray03_VOL05_08: 8 Vector__XXX
 SG_ cell08 : 55|16@0+ (1,0) [0|5000] "V" Vector__XXX
 SG_ cell07 : 39|16@0+ (1,0) [0|5000] "V" Vector__XXX
 SG_ cell06 : 23|16@0+ (1,0) [0|5000] "V" Vector__XXX
 SG_ cell05 : 7|16@0+ (1,0) [0|5000] "V" Vector__XXX

BO_ 417 Tray06_VOL01_4: 8 Vector__XXX
 SG_ cell04 : 55|16@0+ (1,0) [0|5000] "V" Vector__XXX
 SG_ cell03 : 39|16@0+ (1,0) [0|5000] "V" Vector__XXX
 SG_ cell02 : 23|16@0+ (1,0) [0|5000] "V" Vector__XXX
 SG_ cell01 : 7|16@0+ (1,0) [0|5000] "V" Vector__XXX

BO_ 385 Tray05_VOL01_4: 8 Vector__XXX
 SG_ cell04 : 55|16@0+ (1,0) [0|5000] "V" Vector__XXX
 SG_ cell03 : 39|16@0+ (1,0) [0|5000] "V" Vector__XXX
 SG_ cell02 : 23|16@0+ (1,0) [0|5000] "V" Vector__XXX
 SG_ cell01 : 7|16@0+ (1,0) [0|5000] "V" Vector__XXX

BO_ 353 Tray04_VOL01_4: 8 Vector__XXX
 SG_ cell04 : 55|16@0+ (1,0) [0|5000] "V" Vector__XXX
 SG_ cell03 : 39|16@0+ (1,0) [0|5000] "V" Vector__XXX
 SG_ cell02 : 23|16@0+ (1,0) [0|5000] "V" Vector__XXX
 SG_ cell01 : 7|16@0+ (1,0) [0|5000] "V" Vector__XXX

BO_ 321 Tray03_VOL01_4: 8 Vector__XXX
 SG_ cell04 : 55|16@0+ (1,0) [0|5000] "V" Vector__XXX
 SG_ cell03 : 39|16@0+ (1,0) [0|5000] "V" Vector__XXX
 SG_ cell02 : 23|16@0+ (1,0) [0|5000] "V" Vector__XXX
 SG_ cell01 : 7|16@0+ (1,0) [0|5000] "V" Vector__XXX

BO_ 300 Tray02_VOL45_48: 4 Vector__XXX
 SG_ cell46 : 23|16@0+ (1,0) [0|5000] "V" Vector__XXX
 SG_ cell45 : 7|16@0+ (1,0) [0|5000] "V" Vector__XXX

BO_ 299 Tray02_VOL41_44: 8 Vector__XXX
 SG_ cell44 : 55|16@0+ (1,0) [0|5000] "V" Vector__XXX
 SG_ cell43 : 39|16@0+ (1,0) [0|5000] "V" Vector__XXX
 SG_ cell42 : 23|16@0+ (1,0) [0|5000] "V" Vector__XXX
 SG_ cell41 : 7|16@0+ (1,0) [0|5000] "V" Vector__XXX

BO_ 298 Tray02_VOL37_40: 8 Vector__XXX
 SG_ cell40 : 55|16@0+ (1,0) [0|5000] "V" Vector__XXX
 SG_ cell39 : 39|16@0+ (1,0) [0|5000] "V" Vector__XXX
 SG_ cell38 : 23|16@0+ (1,0) [0|5000] "V" Vector__XXX
 SG_ cell37 : 7|16@0+ (1,0) [0|5000] "V" Vector__XXX

BO_ 297 Tray02_VOL33_36: 8 Vector__XXX
 SG_ cell36 : 55|16@0+ (1,0) [0|5000] "V" Vector__XXX
 SG_ cell35 : 39|16@0+ (1,0) [0|5000] "V" Vector__XXX
 SG_ cell34 : 23|16@0+ (1,0) [0|5000] "V" Vector__XXX
 SG_ cell33 : 7|16@0+ (1,0) [0|5000] "V" Vector__XXX

BO_ 296 Tray02_VOL29_32: 8 Vector__XXX
 SG_ cell32 : 55|16@0+ (1,0) [0|5000] "V" Vector__XXX
 SG_ cell31 : 39|16@0+ (1,0) [0|5000] "V" Vector__XXX
 SG_ cell30 : 23|16@0+ (1,0) [0|5000] "V" Vector__XXX
 SG_ cell29 : 7|16@0+ (1,0) [0|5000] "V" Vector__XXX

BO_ 295 Tray02_VOL25_28: 8 Vector__XXX
 SG_ cell28 : 55|16@0+ (1,0) [0|5000] "V" Vector__XXX
 SG_ cell27 : 39|16@0+ (1,0) [0|5000] "V" Vector__XXX
 SG_ cell26 : 23|16@0+ (1,0) [0|5000] "V" Vector__XXX
 SG_ cell25 : 7|16@0+ (1,0) [0|5000] "V" Vector__XXX

BO_ 294 Tray02_VOL21_24: 8 Vector__XXX
 SG_ cell24 : 55|16@0+ (1,0) [0|5000] "V" Vector__XXX
 SG_ cell23 : 39|16@0+ (1,0) [0|5000] "V" Vector__XXX
 SG_ cell22 : 23|16@0+ (1,0) [0|5000] "V" Vector__XXX
 SG_ cell21 : 7|16@0+ (1,0) [0|5000] "V" Vector__XXX

BO_ 293 Tray02_VOL17_20: 8 Vector__XXX
 SG_ cell20 : 55|16@0+ (1,0) [0|5000] "V" Vector__XXX
 SG_ cell19 : 39|16@0+ (1,0) [0|5000] "V" Vector__XXX
 SG_ cell18 : 23|16@0+ (1,0) [0|5000] "V" Vector__XXX
 SG_ cell17 : 7|16@0+ (1,0) [0|5000] "V" Vector__XXX

BO_ 258 Tray01_VOL05_08: 8 Vector__XXX
 SG_ cell08 : 55|16@0+ (1,0) [0|5000] "V" Vector__XXX
 SG_ cell07 : 39|16@0+ (1,0) [0|5000] "V" Vector__XXX
 SG_ cell06 : 23|16@0+ (1,0) [0|5000] "V" Vector__XXX
 SG_ cell05 : 7|16@0+ (1,0) [0|5000] "V" Vector__XXX

BO_ 291 Tray02_VOL09_12: 8 Vector__XXX
 SG_ cell12 : 55|16@0+ (1,0) [0|5000] "V" Vector__XXX
 SG_ cell11 : 39|16@0+ (1,0) [0|5000] "V" Vector__XXX
 SG_ cell10 : 23|16@0+ (1,0) [0|5000] "V" Vector__XXX
 SG_ cell09 : 7|16@0+ (1,0) [0|5000] "V" Vector__XXX

BO_ 292 Tray02_VOL13_16: 8 Vector__XXX
 SG_ cell16 : 55|16@0- (1,0) [0|5000] "V" Vector__XXX
 SG_ cell15 : 39|16@0+ (1,0) [0|5000] "V" Vector__XXX
 SG_ cell14 : 23|16@0+ (1,0) [0|5000] "V" Vector__XXX
 SG_ cell13 : 7|16@0+ (1,0) [0|5000] "V" Vector__XXX

BO_ 289 Tray02_VOL01_4: 8 Vector__XXX
 SG_ cell04 : 55|16@0+ (1,0) [0|5000] "V" Vector__XXX
 SG_ cell03 : 39|16@0+ (1,0) [0|5000] "V" Vector__XXX
 SG_ cell02 : 23|16@0+ (1,0) [0|5000] "V" Vector__XXX
 SG_ cell01 : 7|16@0+ (1,0) [0|5000] "V" Vector__XXX

BO_ 273 Tray01_BdTemp: 4 Vector__XXX
 SG_ brdtemp2 : 23|16@0- (1,0) [0|0] "" Vector__XXX
 SG_ brdtemp1 : 7|16@0- (1,0) [0|0] "" Vector__XXX

BO_ 268 Tray01_VOL45_48: 4 Vector__XXX
 SG_ cell46 : 23|16@0+ (1,0) [0|5000] "V" Vector__XXX
 SG_ cell45 : 7|16@0+ (1,0) [0|5000] "V" Vector__XXX

BO_ 267 Tray01_VOL41_44: 8 Vector__XXX
 SG_ cell44 : 55|16@0+ (1,0) [0|5000] "V" Vector__XXX
 SG_ cell43 : 39|16@0+ (1,0) [0|5000] "V" Vector__XXX
 SG_ cell42 : 23|16@0+ (1,0) [0|5000] "V" Vector__XXX
 SG_ cell41 : 7|16@0+ (1,0) [0|5000] "V" Vector__XXX

BO_ 266 Tray01_VOL37_40: 8 Vector__XXX
 SG_ cell40 : 55|16@0+ (1,0) [0|5000] "V" Vector__XXX
 SG_ cell39 : 39|16@0+ (1,0) [0|5000] "V" Vector__XXX
 SG_ cell38 : 23|16@0+ (1,0) [0|5000] "V" Vector__XXX
 SG_ cell37 : 7|16@0+ (1,0) [0|5000] "V" Vector__XXX

BO_ 265 Tray01_VOL33_36: 8 Vector__XXX
 SG_ cell36 : 55|16@0+ (1,0) [0|5000] "V" Vector__XXX
 SG_ cell35 : 39|16@0+ (1,0) [0|5000] "V" Vector__XXX
 SG_ cell34 : 23|16@0+ (1,0) [0|5000] "V" Vector__XXX
 SG_ cell33 : 7|16@0+ (1,0) [0|5000] "V" Vector__XXX

BO_ 264 Tray01_VOL29_32: 8 Vector__XXX
 SG_ cell32 : 55|16@0+ (1,0) [0|5000] "V" Vector__XXX
 SG_ cell31 : 39|16@0+ (1,0) [0|5000] "V" Vector__XXX
 SG_ cell30 : 23|16@0+ (1,0) [0|5000] "V" Vector__XXX
 SG_ cell29 : 7|16@0+ (1,0) [0|5000] "V" Vector__XXX

BO_ 263 Tray01_VOL25_28: 8 Vector__XXX
 SG_ cell28 : 55|16@0+ (1,0) [0|5000] "V" Vector__XXX
 SG_ cell27 : 39|16@0+ (1,0) [0|5000] "V" Vector__XXX
 SG_ cell26 : 23|16@0+ (1,0) [0|5000] "V" Vector__XXX
 SG_ cell25 : 7|16@0+ (1,0) [0|5000] "V" Vector__XXX

BO_ 262 Tray01_VOL21_24: 8 Vector__XXX
 SG_ cell24 : 55|16@0+ (1,0) [0|5000] "V" Vector__XXX
 SG_ cell23 : 39|16@0+ (1,0) [0|5000] "V" Vector__XXX
 SG_ cell22 : 23|16@0+ (1,0) [0|5000] "V" Vector__XXX
 SG_ cell21 : 7|16@0+ (1,0) [0|5000] "V" Vector__XXX

BO_ 272 Tray01_Temp: 8 Vector__XXX
 SG_ temp4 : 55|16@0- (1,0) [0|0] "" Vector__XXX
 SG_ temp3 : 39|16@0- (1,0) [0|0] "" Vector__XXX
 SG_ temp2 : 23|16@0- (1,0) [0|0] "" Vector__XXX
 SG_ temp1 : 7|16@0- (1,0) [0|0] "" Vector__XXX

BO_ 261 Tray01_VOL17_20: 8 Vector__XXX
 SG_ cell20 : 55|16@0+ (1,0) [0|5000] "V" Vector__XXX
 SG_ cell19 : 39|16@0+ (1,0) [0|5000] "V" Vector__XXX
 SG_ cell18 : 23|16@0+ (1,0) [0|5000] "V" Vector__XXX
 SG_ cell17 : 7|16@0+ (1,0) [0|5000] "V" Vector__XXX

BO_ 260 Tray01_VOL13_16: 8 Vector__XXX
 SG_ cell16 : 55|16@0- (1,0) [0|5000] "V" Vector__XXX
 SG_ cell15 : 39|16@0+ (1,0) [0|5000] "V" Vector__XXX
 SG_ cell14 : 23|16@0+ (1,0) [0|5000] "V" Vector__XXX
 SG_ cell13 : 7|16@0+ (1,0) [0|5000] "V" Vector__XXX

BO_ 259 Tray01_VOL09_12: 8 Vector__XXX
 SG_ cell12 : 55|16@0+ (1,0) [0|5000] "V" Vector__XXX
 SG_ cell11 : 39|16@0+ (1,0) [0|5000] "V" Vector__XXX
 SG_ cell10 : 23|16@0+ (1,0) [0|5000] "V" Vector__XXX
 SG_ cell09 : 7|16@0+ (1,0) [0|5000] "V" Vector__XXX

BO_ 290 Tray02_VOL05_08: 8 Vector__XXX
 SG_ cell08 : 55|16@0+ (1,0) [0|5000] "V" Vector__XXX
 SG_ cell07 : 39|16@0+ (1,0) [0|5000] "V" Vector__XXX
 SG_ cell06 : 23|16@0+ (1,0) [0|5000] "V" Vector__XXX
 SG_ cell05 : 7|16@0+ (1,0) [0|5000] "V" Vector__XXX

BO_ 257 Tray01_VOL01_4: 8 Vector__XXX
 SG_ cell04 : 55|16@0+ (1,0) [0|5000] "V" Vector__XXX
 SG_ cell03 : 39|16@0+ (1,0) [0|5000] "V" Vector__XXX
 SG_ cell02 : 23|16@0+ (1,0) [0|5000] "V" Vector__XXX
 SG_ cell01 : 7|16@0+ (1,0) [0|5000] "V" Vector__XXX

EV_ Tray5_CB: 0 [0|0] "" 0 1 DUMMY_NODE_VECTOR0 Vector__XXX;

EV_ Tray4_CB: 0 [0|0] "" 0 2 DUMMY_NODE_VECTOR0 Vector__XXX;

EV_ Tray13_CB: 0 [0|0] "" 0 3 DUMMY_NODE_VECTOR0 Vector__XXX;

EV_ Tray12_CB: 0 [0|0] "" 0 4 DUMMY_NODE_VECTOR0 Vector__XXX;

EV_ Tray11_CB: 0 [0|0] "" 0 5 DUMMY_NODE_VECTOR0 Vector__XXX;

EV_ Tray10_CB: 0 [0|0] "" 0 6 DUMMY_NODE_VECTOR0 Vector__XXX;

EV_ Tray9_CB: 0 [0|0] "" 0 7 DUMMY_NODE_VECTOR0 Vector__XXX;

EV_ Tray8_CB: 0 [0|0] "" 0 8 DUMMY_NODE_VECTOR0 Vector__XXX;

EV_ Tray7_CB: 0 [0|0] "" 0 9 DUMMY_NODE_VECTOR0 Vector__XXX;

EV_ Tray6_CB: 0 [0|0] "" 0 10 DUMMY_NODE_VECTOR0 Vector__XXX;

EV_ Tray3_CB: 0 [0|0] "" 0 11 DUMMY_NODE_VECTOR0 Vector__XXX;

EV_ Tray2_CB: 0 [0|0] "" 0 12 DUMMY_NODE_VECTOR0 Vector__XXX;

EV_ Tray1_CB: 0 [0|0] "" 0 13 DUMMY_NODE_VECTOR0 Vector__XXX;

CM_ BO_ 3221225472 "This is a message for not used signals, created by Vector CANdb++ DBC OLE DB Provider.";
